VERSION ""

NS_ :

BS_:

BU_: AMB BMS ECU TEL OBC MEMORATOR MDI MC STR DRD MPPT DIST MST HVC

BO_ 808 HvcMcPrecharge: 4 HVC
 SG_ MotorPrechargeVoltage : 7|32@0- (1,0) [-2147483648|2147483647] "mV" Vector__XXX

BO_ 809 HvcMpptPrecharge: 4 HVC
 SG_ MpptPrechargeVoltage : 7|32@0- (1,0) [-2147483648|2147483647] "mV" Vector__XXX

BO_ 801 HVC_Fault: 3 HVC
 SG_ WatchdogFired : 0|1@1+ (1,0) [0|1] "" Vector__XXX
 SG_ DcdcFault : 1|1@1+ (1,0) [0|1] "" Vector__XXX
 SG_ DistFaultFlag : 2|1@1+ (1,0) [0|1] "" Vector__XXX
 SG_ UndercurrentFault : 3|1@1+ (1,0) [0|1] "" Vector__XXX
 SG_ OvercurrentFault : 4|1@1+ (1,0) [0|1] "" Vector__XXX
 SG_ MasterboardFault : 5|1@1+ (1,0) [0|1] "" Vector__XXX
 SG_ ImdFault : 6|1@1+ (1,0) [0|1] "" Vector__XXX
 SG_ EstopFault : 7|1@1+ (1,0) [0|1] "" Vector__XXX
 SG_ TelHeartbeatTimeout : 8|1@1+ (1,0) [0|1] "" Vector__XXX
 SG_ LvPowerupTimeout : 9|1@1+ (1,0) [0|1] "" Vector__XXX
 SG_ MpptPrechargeTimeout : 10|1@1+ (1,0) [0|1] "" Vector__XXX
 SG_ MotorPrechargeTimeout : 11|1@1+ (1,0) [0|1] "" Vector__XXX
 SG_ MotorDischargeTimeout : 12|1@1+ (1,0) [0|1] "" Vector__XXX
 SG_ MstCheckTimeout : 13|1@1+ (1,0) [0|1] "" Vector__XXX
 SG_ MstReadyTimeout : 14|1@1+ (1,0) [0|1] "" Vector__XXX
 SG_ MvpLvPowerupTimeout : 15|1@1+ (1,0) [0|1] "" Vector__XXX
 SG_ DcdcThermistorFault : 21|1@1+ (1,0) [0|1] "" Vector__XXX
 SG_ DistHeartbeatTimeout : 22|1@1+ (1,0) [0|1] "" Vector__XXX
 SG_ MstHeartbeatTimeout : 23|1@1+ (1,0) [0|1] "" Vector__XXX

BO_ 802 HVCHeartbeat: 4 HVC
 SG_ HVCTimeSinceBootUp : 23|16@0+ (1,0) [0|65535] "" Vector__XXX

BO_ 803 HVCLvPowerupSent: 1 HVC
 SG_ HVCLvPowerupSent : 0|8@1+ (1,0) [0|1] "" Vector__XXX

BO_ 804 HvcStatus: 1 HVC
 SG_ HVCState : 0|8@1+ (1,0) [0|14] "" Vector__XXX

BO_ 800 HVCShuntCurrent: 4 HVC
 SG_ PackCurrent : 7|32@0- (1,0) [-2147483648|2147483647] "mA" Vector__XXX

BO_ 807 HvcSuppVoltage: 4 HVC
 SG_ SuppVoltage : 7|32@0+ (1,0) [0|4294967295] "mV" Vector__XXX

BO_ 928 DISTHeartBeat: 3 DIST
 SG_ DISTHeartbeat : 0|8@1+ (1,0) [0|255] "" Vector__XXX
 SG_ DISTHeartbeatCounter : 15|16@0+ (1,0) [0|65535] "" Vector__XXX

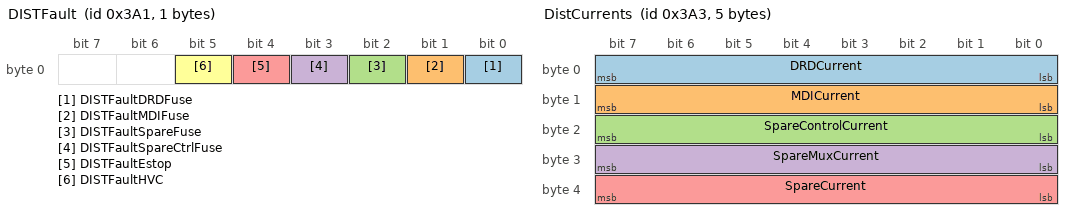
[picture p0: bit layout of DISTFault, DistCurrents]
BO_ 929 DISTFault: 1 DIST
 SG_ DISTFaultDRDFuse : 0|1@1+ (1,0) [0|1] "" Vector__XXX
 SG_ DISTFaultMDIFuse : 1|1@1+ (1,0) [0|1] "" Vector__XXX
 SG_ DISTFaultSpareFuse : 2|1@1+ (1,0) [0|1] "" Vector__XXX
 SG_ DISTFaultSpareCtrlFuse : 3|1@1+ (1,0) [0|1] "" Vector__XXX
 SG_ DISTFaultEstop : 4|1@1+ (1,0) [0|1] "" Vector__XXX
 SG_ DISTFaultHVC : 5|1@1+ (1,0) [0|1] "" Vector__XXX

BO_ 930 DISTLVOn: 1 DIST
 SG_ DISTLVOn : 0|8@1+ (1,0) [0|1] "" Vector__XXX

BO_ 931 DistCurrents: 5 DIST
 SG_ DRDCurrent : 0|8@1+ (5,0) [0|1275] "mA" Vector__XXX
 SG_ MDICurrent : 8|8@1+ (5,0) [0|1275] "mA" Vector__XXX
 SG_ SpareControlCurrent : 16|8@1+ (5,0) [0|1275] "mA" Vector__XXX
 SG_ SpareMuxCurrent : 24|8@1+ (5,0) [0|1275] "mA" Vector__XXX
 SG_ SpareCurrent : 32|8@1+ (5,0) [0|1275] "mA" Vector__XXX

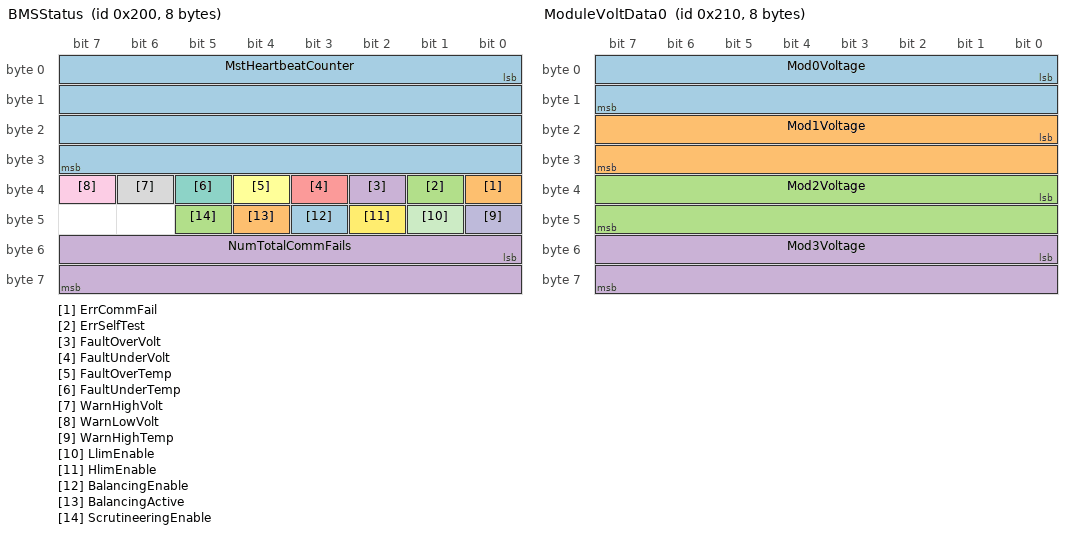
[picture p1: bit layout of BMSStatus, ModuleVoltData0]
BO_ 512 BMSStatus: 8 MST
 SG_ MstHeartbeatCounter : 0|32@1+ (1,0) [0|4294967295] "" Vector__XXX
 SG_ ErrCommFail : 32|1@1+ (1,0) [0|1] "" Vector__XXX
 SG_ ErrSelfTest : 33|1@1+ (1,0) [0|1] "" Vector__XXX
 SG_ FaultOverVolt : 34|1@1+ (1,0) [0|1] "" Vector__XXX
 SG_ FaultUnderVolt : 35|1@1+ (1,0) [0|1] "" Vector__XXX
 SG_ FaultOverTemp : 36|1@1+ (1,0) [0|1] "" Vector__XXX
 SG_ FaultUnderTemp : 37|1@1+ (1,0) [0|1] "" Vector__XXX
 SG_ WarnHighVolt : 38|1@1+ (1,0) [0|1] "" Vector__XXX
 SG_ WarnLowVolt : 39|1@1+ (1,0) [0|1] "" Vector__XXX
 SG_ WarnHighTemp : 40|1@1+ (1,0) [0|1] "" Vector__XXX
 SG_ LlimEnable : 41|1@1+ (1,0) [0|1] "" Vector__XXX
 SG_ HlimEnable : 42|1@1+ (1,0) [0|1] "" Vector__XXX
 SG_ BalancingEnable : 43|1@1+ (1,0) [0|1] "" Vector__XXX
 SG_ BalancingActive : 44|1@1+ (1,0) [0|1] "" Vector__XXX
 SG_ ScrutineeringEnable : 45|1@1+ (1,0) [0|1] "" Vector__XXX
 SG_ NumTotalCommFails : 48|16@1+ (1,0) [0|65535] "" Vector__XXX

BO_ 513 VoltSummary: 6 MST
 SG_ TotalVoltage : 0|32@1+ (1,0) [0|4294967295] "mV" Vector__XXX
 SG_ MinVoltModuleIdx : 32|8@1+ (1,0) [0|255] "" Vector__XXX
 SG_ MaxVoltModuleIdx : 40|8@1+ (1,0) [0|255] "" Vector__XXX

BO_ 514 TempSummary: 4 MST
 SG_ AvgTemp : 0|16@1- (1,0) [-32768|32767] "degC" Vector__XXX
 SG_ MinTempModuleIdx : 16|8@1+ (1,0) [0|255] "" Vector__XXX
 SG_ MaxTempModuleIdx : 24|8@1+ (1,0) [0|255] "" Vector__XXX

BO_ 528 ModuleVoltData0: 8 MST
 SG_ Mod0Voltage : 0|16@1+ (1,0) [0|65535] "mV" Vector__XXX
 SG_ Mod1Voltage : 16|16@1+ (1,0) [0|65535] "mV" Vector__XXX
 SG_ Mod2Voltage : 32|16@1+ (1,0) [0|65535] "mV" Vector__XXX
 SG_ Mod3Voltage : 48|16@1+ (1,0) [0|65535] "mV" Vector__XXX

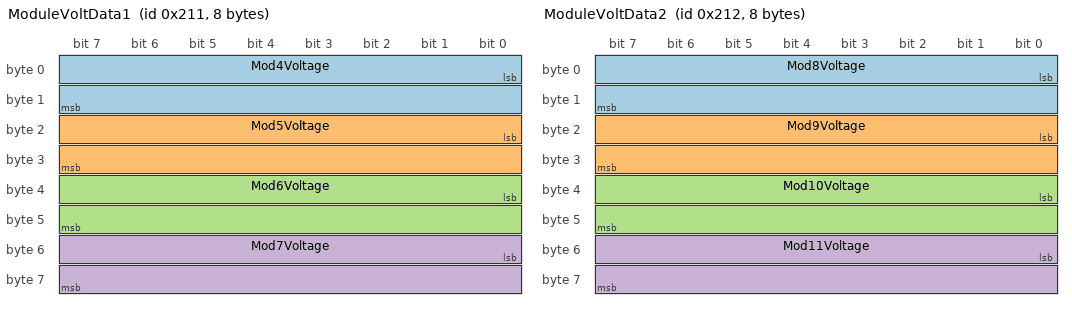
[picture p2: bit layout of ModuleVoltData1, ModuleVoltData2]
BO_ 529 ModuleVoltData1: 8 MST
 SG_ Mod4Voltage : 0|16@1+ (1,0) [0|65535] "mV" Vector__XXX
 SG_ Mod5Voltage : 16|16@1+ (1,0) [0|65535] "mV" Vector__XXX
 SG_ Mod6Voltage : 32|16@1+ (1,0) [0|65535] "mV" Vector__XXX
 SG_ Mod7Voltage : 48|16@1+ (1,0) [0|65535] "mV" Vector__XXX

BO_ 530 ModuleVoltData2: 8 MST
 SG_ Mod8Voltage : 0|16@1+ (1,0) [0|65535] "mV" Vector__XXX
 SG_ Mod9Voltage : 16|16@1+ (1,0) [0|65535] "mV" Vector__XXX
 SG_ Mod10Voltage : 32|16@1+ (1,0) [0|65535] "mV" Vector__XXX
 SG_ Mod11Voltage : 48|16@1+ (1,0) [0|65535] "mV" Vector__XXX

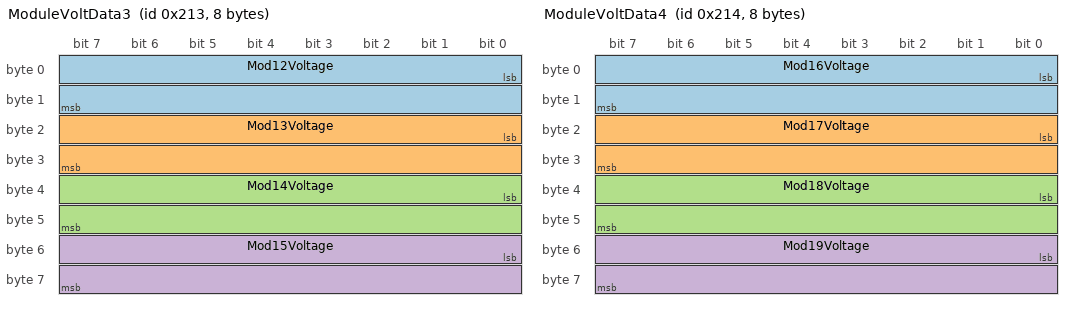
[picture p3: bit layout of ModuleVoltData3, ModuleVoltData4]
BO_ 531 ModuleVoltData3: 8 MST
 SG_ Mod12Voltage : 0|16@1+ (1,0) [0|65535] "mV" Vector__XXX
 SG_ Mod13Voltage : 16|16@1+ (1,0) [0|65535] "mV" Vector__XXX
 SG_ Mod14Voltage : 32|16@1+ (1,0) [0|65535] "mV" Vector__XXX
 SG_ Mod15Voltage : 48|16@1+ (1,0) [0|65535] "mV" Vector__XXX

BO_ 532 ModuleVoltData4: 8 MST
 SG_ Mod16Voltage : 0|16@1+ (1,0) [0|65535] "mV" Vector__XXX
 SG_ Mod17Voltage : 16|16@1+ (1,0) [0|65535] "mV" Vector__XXX
 SG_ Mod18Voltage : 32|16@1+ (1,0) [0|65535] "mV" Vector__XXX
 SG_ Mod19Voltage : 48|16@1+ (1,0) [0|65535] "mV" Vector__XXX

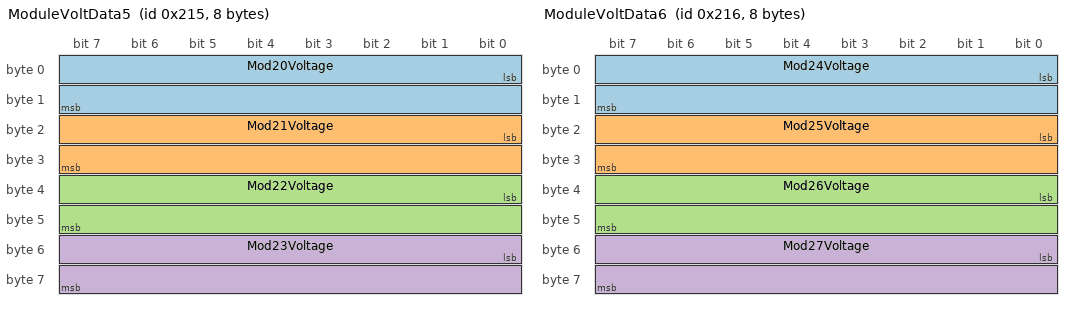
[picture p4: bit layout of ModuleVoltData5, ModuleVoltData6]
BO_ 533 ModuleVoltData5: 8 MST
 SG_ Mod20Voltage : 0|16@1+ (1,0) [0|65535] "mV" Vector__XXX
 SG_ Mod21Voltage : 16|16@1+ (1,0) [0|65535] "mV" Vector__XXX
 SG_ Mod22Voltage : 32|16@1+ (1,0) [0|65535] "mV" Vector__XXX
 SG_ Mod23Voltage : 48|16@1+ (1,0) [0|65535] "mV" Vector__XXX

BO_ 534 ModuleVoltData6: 8 MST
 SG_ Mod24Voltage : 0|16@1+ (1,0) [0|65535] "mV" Vector__XXX
 SG_ Mod25Voltage : 16|16@1+ (1,0) [0|65535] "mV" Vector__XXX
 SG_ Mod26Voltage : 32|16@1+ (1,0) [0|65535] "mV" Vector__XXX
 SG_ Mod27Voltage : 48|16@1+ (1,0) [0|65535] "mV" Vector__XXX

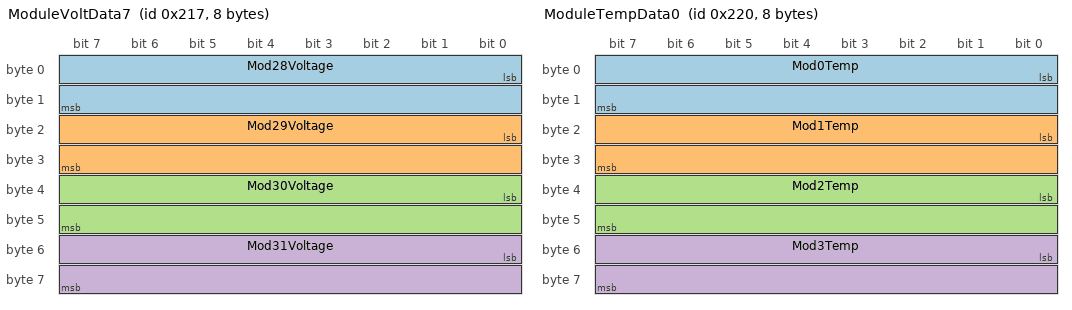
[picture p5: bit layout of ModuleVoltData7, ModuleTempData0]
BO_ 535 ModuleVoltData7: 8 MST
 SG_ Mod28Voltage : 0|16@1+ (1,0) [0|65535] "mV" Vector__XXX
 SG_ Mod29Voltage : 16|16@1+ (1,0) [0|65535] "mV" Vector__XXX
 SG_ Mod30Voltage : 32|16@1+ (1,0) [0|65535] "mV" Vector__XXX
 SG_ Mod31Voltage : 48|16@1+ (1,0) [0|65535] "mV" Vector__XXX

BO_ 544 ModuleTempData0: 8 MST
 SG_ Mod0Temp : 0|16@1- (1,0) [-32768|32767] "degC" Vector__XXX
 SG_ Mod1Temp : 16|16@1- (1,0) [-32768|32767] "degC" Vector__XXX
 SG_ Mod2Temp : 32|16@1- (1,0) [-32768|32767] "degC" Vector__XXX
 SG_ Mod3Temp : 48|16@1- (1,0) [-32768|32767] "degC" Vector__XXX

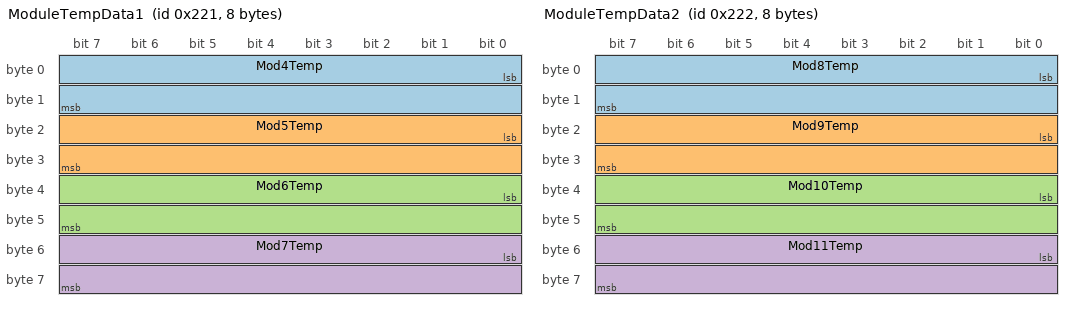
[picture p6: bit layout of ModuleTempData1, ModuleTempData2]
BO_ 545 ModuleTempData1: 8 MST
 SG_ Mod4Temp : 0|16@1- (1,0) [-32768|32767] "degC" Vector__XXX
 SG_ Mod5Temp : 16|16@1- (1,0) [-32768|32767] "degC" Vector__XXX
 SG_ Mod6Temp : 32|16@1- (1,0) [-32768|32767] "degC" Vector__XXX
 SG_ Mod7Temp : 48|16@1- (1,0) [-32768|32767] "degC" Vector__XXX

BO_ 546 ModuleTempData2: 8 MST
 SG_ Mod8Temp : 0|16@1- (1,0) [-32768|32767] "degC" Vector__XXX
 SG_ Mod9Temp : 16|16@1- (1,0) [-32768|32767] "degC" Vector__XXX
 SG_ Mod10Temp : 32|16@1- (1,0) [-32768|32767] "degC" Vector__XXX
 SG_ Mod11Temp : 48|16@1- (1,0) [-32768|32767] "degC" Vector__XXX

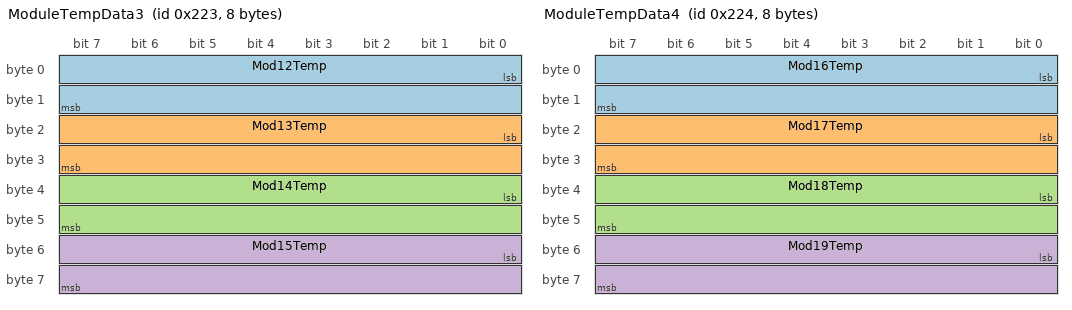
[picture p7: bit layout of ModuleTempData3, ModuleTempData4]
BO_ 547 ModuleTempData3: 8 MST
 SG_ Mod12Temp : 0|16@1- (1,0) [-32768|32767] "degC" Vector__XXX
 SG_ Mod13Temp : 16|16@1- (1,0) [-32768|32767] "degC" Vector__XXX
 SG_ Mod14Temp : 32|16@1- (1,0) [-32768|32767] "degC" Vector__XXX
 SG_ Mod15Temp : 48|16@1- (1,0) [-32768|32767] "degC" Vector__XXX

BO_ 548 ModuleTempData4: 8 MST
 SG_ Mod16Temp : 0|16@1- (1,0) [-32768|32767] "degC" Vector__XXX
 SG_ Mod17Temp : 16|16@1- (1,0) [-32768|32767] "degC" Vector__XXX
 SG_ Mod18Temp : 32|16@1- (1,0) [-32768|32767] "degC" Vector__XXX
 SG_ Mod19Temp : 48|16@1- (1,0) [-32768|32767] "degC" Vector__XXX

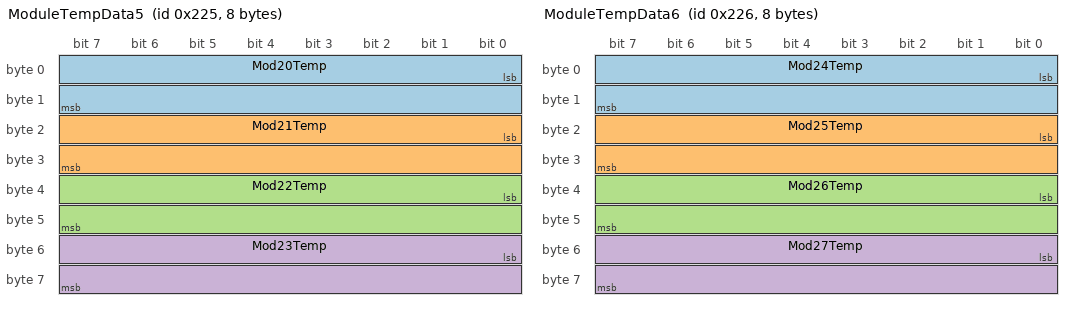
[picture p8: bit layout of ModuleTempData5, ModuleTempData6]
BO_ 549 ModuleTempData5: 8 MST
 SG_ Mod20Temp : 0|16@1- (1,0) [-32768|32767] "degC" Vector__XXX
 SG_ Mod21Temp : 16|16@1- (1,0) [-32768|32767] "degC" Vector__XXX
 SG_ Mod22Temp : 32|16@1- (1,0) [-32768|32767] "degC" Vector__XXX
 SG_ Mod23Temp : 48|16@1- (1,0) [-32768|32767] "degC" Vector__XXX

BO_ 550 ModuleTempData6: 8 MST
 SG_ Mod24Temp : 0|16@1- (1,0) [-32768|32767] "degC" Vector__XXX
 SG_ Mod25Temp : 16|16@1- (1,0) [-32768|32767] "degC" Vector__XXX
 SG_ Mod26Temp : 32|16@1- (1,0) [-32768|32767] "degC" Vector__XXX
 SG_ Mod27Temp : 48|16@1- (1,0) [-32768|32767] "degC" Vector__XXX

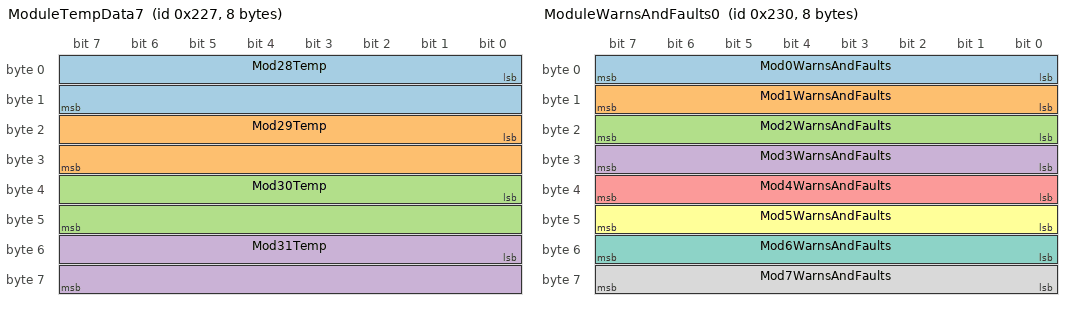
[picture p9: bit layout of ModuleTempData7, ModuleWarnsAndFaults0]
BO_ 551 ModuleTempData7: 8 MST
 SG_ Mod28Temp : 0|16@1- (1,0) [-32768|32767] "degC" Vector__XXX
 SG_ Mod29Temp : 16|16@1- (1,0) [-32768|32767] "degC" Vector__XXX
 SG_ Mod30Temp : 32|16@1- (1,0) [-32768|32767] "degC" Vector__XXX
 SG_ Mod31Temp : 48|16@1- (1,0) [-32768|32767] "degC" Vector__XXX

BO_ 560 ModuleWarnsAndFaults0: 8 MST
 SG_ Mod0WarnsAndFaults : 0|8@1+ (1,0) [0|255] "" Vector__XXX
 SG_ Mod1WarnsAndFaults : 8|8@1+ (1,0) [0|255] "" Vector__XXX
 SG_ Mod2WarnsAndFaults : 16|8@1+ (1,0) [0|255] "" Vector__XXX
 SG_ Mod3WarnsAndFaults : 24|8@1+ (1,0) [0|255] "" Vector__XXX
 SG_ Mod4WarnsAndFaults : 32|8@1+ (1,0) [0|255] "" Vector__XXX
 SG_ Mod5WarnsAndFaults : 40|8@1+ (1,0) [0|255] "" Vector__XXX
 SG_ Mod6WarnsAndFaults : 48|8@1+ (1,0) [0|255] "" Vector__XXX
 SG_ Mod7WarnsAndFaults : 56|8@1+ (1,0) [0|255] "" Vector__XXX

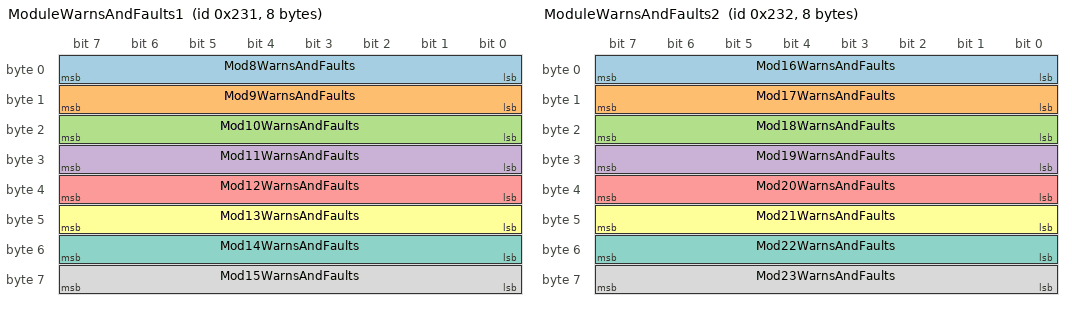
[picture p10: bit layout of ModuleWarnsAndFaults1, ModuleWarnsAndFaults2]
BO_ 561 ModuleWarnsAndFaults1: 8 MST
 SG_ Mod8WarnsAndFaults : 0|8@1+ (1,0) [0|255] "" Vector__XXX
 SG_ Mod9WarnsAndFaults : 8|8@1+ (1,0) [0|255] "" Vector__XXX
 SG_ Mod10WarnsAndFaults : 16|8@1+ (1,0) [0|255] "" Vector__XXX
 SG_ Mod11WarnsAndFaults : 24|8@1+ (1,0) [0|255] "" Vector__XXX
 SG_ Mod12WarnsAndFaults : 32|8@1+ (1,0) [0|255] "" Vector__XXX
 SG_ Mod13WarnsAndFaults : 40|8@1+ (1,0) [0|255] "" Vector__XXX
 SG_ Mod14WarnsAndFaults : 48|8@1+ (1,0) [0|255] "" Vector__XXX
 SG_ Mod15WarnsAndFaults : 56|8@1+ (1,0) [0|255] "" Vector__XXX

BO_ 562 ModuleWarnsAndFaults2: 8 MST
 SG_ Mod16WarnsAndFaults : 0|8@1+ (1,0) [0|255] "" Vector__XXX
 SG_ Mod17WarnsAndFaults : 8|8@1+ (1,0) [0|255] "" Vector__XXX
 SG_ Mod18WarnsAndFaults : 16|8@1+ (1,0) [0|255] "" Vector__XXX
 SG_ Mod19WarnsAndFaults : 24|8@1+ (1,0) [0|255] "" Vector__XXX
 SG_ Mod20WarnsAndFaults : 32|8@1+ (1,0) [0|255] "" Vector__XXX
 SG_ Mod21WarnsAndFaults : 40|8@1+ (1,0) [0|255] "" Vector__XXX
 SG_ Mod22WarnsAndFaults : 48|8@1+ (1,0) [0|255] "" Vector__XXX
 SG_ Mod23WarnsAndFaults : 56|8@1+ (1,0) [0|255] "" Vector__XXX

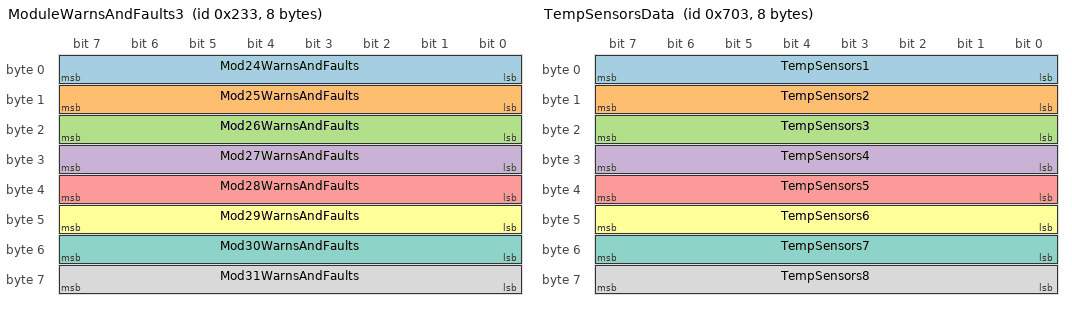
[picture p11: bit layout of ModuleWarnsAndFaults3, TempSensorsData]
BO_ 563 ModuleWarnsAndFaults3: 8 MST
 SG_ Mod24WarnsAndFaults : 0|8@1+ (1,0) [0|255] "" Vector__XXX
 SG_ Mod25WarnsAndFaults : 8|8@1+ (1,0) [0|255] "" Vector__XXX
 SG_ Mod26WarnsAndFaults : 16|8@1+ (1,0) [0|255] "" Vector__XXX
 SG_ Mod27WarnsAndFaults : 24|8@1+ (1,0) [0|255] "" Vector__XXX
 SG_ Mod28WarnsAndFaults : 32|8@1+ (1,0) [0|255] "" Vector__XXX
 SG_ Mod29WarnsAndFaults : 40|8@1+ (1,0) [0|255] "" Vector__XXX
 SG_ Mod30WarnsAndFaults : 48|8@1+ (1,0) [0|255] "" Vector__XXX
 SG_ Mod31WarnsAndFaults : 56|8@1+ (1,0) [0|255] "" Vector__XXX

BO_ 515 BalanceData: 4 MST
 SG_ BalanceBitmap : 0|32@1+ (1,0) [0|4294967295] "" Vector__XXX

BO_ 1793 VoltageSensorsData: 8 AMB
 SG_ VoltSensor1 : 0|32@1- (1,0) [0|0] "V" Vector__XXX
 SG_ VoltSensor2 : 32|32@1- (1,0) [0|0] "V" Vector__XXX

BO_ 1794 CurrentSensorsData: 8 AMB
 SG_ CurrentSensor1 : 0|32@1- (1,0) [0|0] "A" Vector__XXX
 SG_ CurrentSensor2 : 32|32@1- (1,0) [0|0] "A" Vector__XXX

BO_ 1795 TempSensorsData: 8 AMB
 SG_ TempSensors1 : 0|8@1+ (1,0) [0|0] "C" Vector__XXX
 SG_ TempSensors2 : 8|8@1+ (1,0) [0|0] "C" Vector__XXX
 SG_ TempSensors3 : 16|8@1+ (1,0) [0|0] "C" Vector__XXX
 SG_ TempSensors4 : 24|8@1+ (1,0) [0|0] "C" Vector__XXX
 SG_ TempSensors5 : 32|8@1+ (1,0) [0|0] "C" Vector__XXX
 SG_ TempSensors6 : 40|8@1+ (1,0) [0|0] "C" Vector__XXX
 SG_ TempSensors7 : 48|8@1+ (1,0) [0|0] "C" Vector__XXX
 SG_ TempSensors8 : 56|8@1+ (1,0) [0|0] "C" Vector__XXX

BO_ 1570 Faults: 7 BMS
 SG_ SlaveBoardComm : 0|1@1+ (1,0) [0|0] "" Vector__XXX
 SG_ BMSSelfTest : 1|1@1+ (1,0) [0|0] "" Vector__XXX
 SG_ OverTemp : 2|1@1+ (1,0) [0|0] "" Vector__XXX
 SG_ UnderVoltage : 3|1@1+ (1,0) [0|0] "" Vector__XXX
 SG_ OverVoltage : 4|1@1+ (1,0) [0|0] "" Vector__XXX
 SG_ IsoLost : 5|1@1+ (1,0) [0|0] "" Vector__XXX
 SG_ ChargeOvercurrent : 6|1@1+ (1,0) [0|0] "" Vector__XXX
 SG_ VoltOutofRange : 7|1@1+ (1,0) [0|0] "" Vector__XXX
 SG_ TempOutofRange : 8|1@1+ (1,0) [0|0] "" Vector__XXX
 SG_ PackBalancingActive : 9|1@1+ (1,0) [0|0] "" Vector__XXX
 SG_ LLIMActive : 10|1@1+ (1,0) [0|0] "" Vector__XXX
 SG_ HLIMActive : 11|1@1+ (1,0) [0|0] "" Vector__XXX
 SG_ ChargeOverTemp : 12|1@1+ (1,0) [0|0] "" Vector__XXX
 SG_ LowVoltage : 13|1@1+ (1,0) [0|0] "" Vector__XXX
 SG_ HighVoltage : 14|1@1+ (1,0) [0|0] "" Vector__XXX
 SG_ LowTemp : 15|1@1+ (1,0) [0|0] "" Vector__XXX
 SG_ HighTemp : 16|1@1+ (1,0) [0|0] "" Vector__XXX
 SG_ RequestRegenOff : 17|1@1+ (1,0) [0|0] "" Vector__XXX
 SG_ NoECUCurrentMessage : 18|1@1+ (1,0) [0|0] "" Vector__XXX

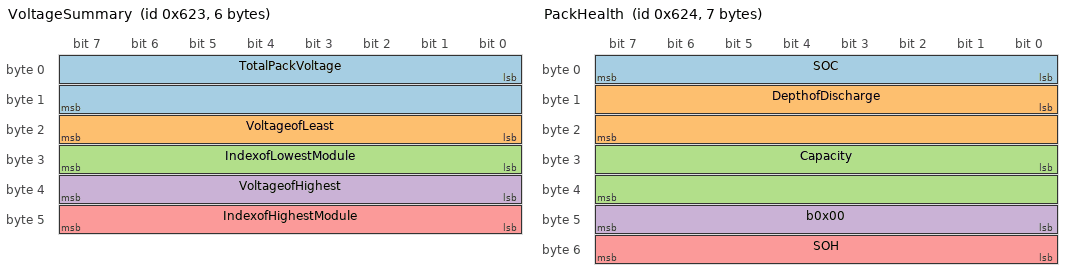
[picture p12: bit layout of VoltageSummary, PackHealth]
BO_ 1571 VoltageSummary: 6 BMS
 SG_ TotalPackVoltage : 0|16@1+ (0.0021367521368,0) [0|140] "V" Vector__XXX
 SG_ VoltageofLeast : 16|8@1+ (0.019607843137,0) [0|5] "V" Vector__XXX
 SG_ IndexofLowestModule : 24|8@1+ (1,0) [0|31] "" Vector__XXX
 SG_ VoltageofHighest : 32|8@1+ (0.019607843137,0) [0|5] "V" Vector__XXX
 SG_ IndexofHighestModule : 40|8@1+ (1,0) [0|31] "" Vector__XXX

BO_ 1572 PackHealth: 7 BMS
 SG_ SOC : 0|8@1+ (1,0) [0|100] "%" Vector__XXX
 SG_ DepthofDischarge : 8|16@1+ (1,0) [0|65] "kAH" Vector__XXX
 SG_ Capacity : 24|16@1+ (1,0) [0|65] "kAH" Vector__XXX
 SG_ b0x00 : 40|8@1+ (1,0) [0|0] "" Vector__XXX
 SG_ SOH : 48|8@1+ (1,0) [0|0] "" Vector__XXX

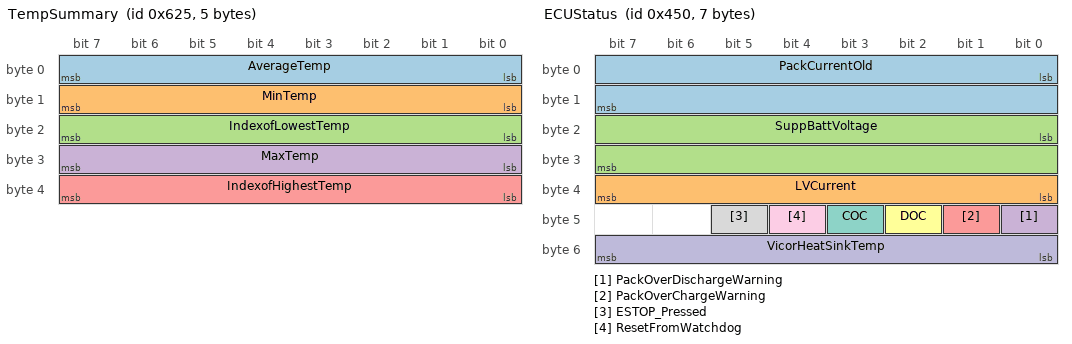
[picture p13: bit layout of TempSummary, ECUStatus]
BO_ 1573 TempSummary: 5 BMS
 SG_ AverageTemp : 0|8@1- (1,0) [-127|127] "C" Vector__XXX
 SG_ MinTemp : 8|8@1- (1,0) [-127|127] "C" Vector__XXX
 SG_ IndexofLowestTemp : 16|8@1+ (1,0) [0|31] "" Vector__XXX
 SG_ MaxTemp : 24|8@1- (1,0) [-127|127] "C" Vector__XXX
 SG_ IndexofHighestTemp : 32|8@1+ (1,0) [0|31] "" Vector__XXX

BO_ 1574 ModuleVoltages: 5 BMS
 SG_ MultiplexingBits M : 0|3@1+ (1,0) [0|0] "" Vector__XXX
 SG_ Voltage1 m0 : 8|8@1+ (0.019607843137,0) [0|5] "V" Vector__XXX
 SG_ Voltage2 m0 : 16|8@1+ (0.019607843137,0) [0|5] "V" Vector__XXX
 SG_ Voltage3 m0 : 24|8@1+ (0.019607843137,0) [0|5] "V" Vector__XXX
 SG_ Voltage4 m0 : 32|8@1+ (0.019607843137,0) [0|5] "V" Vector__XXX
 SG_ Voltage5 m1 : 8|8@1+ (0.019607843137,0) [0|5] "V" Vector__XXX
 SG_ Voltage6 m1 : 16|8@1+ (0.019607843137,0) [0|5] "V" Vector__XXX
 SG_ Voltage7 m1 : 24|8@1+ (0.019607843137,0) [0|5] "V" Vector__XXX
 SG_ Voltage8 m1 : 32|8@1+ (0.019607843137,0) [0|5] "V" Vector__XXX
 SG_ Voltage9 m2 : 8|8@1+ (0.019607843137,0) [0|5] "V" Vector__XXX
 SG_ Voltage10 m2 : 16|8@1+ (0.019607843137,0) [0|5] "V" Vector__XXX
 SG_ Voltage11 m2 : 24|8@1+ (0.019607843137,0) [0|5] "V" Vector__XXX
 SG_ Voltage12 m2 : 32|8@1+ (0.019607843137,0) [0|5] "V" Vector__XXX
 SG_ Voltage13 m3 : 8|8@1+ (0.019607843137,0) [0|5] "V" Vector__XXX
 SG_ Voltage14 m3 : 16|8@1+ (0.019607843137,0) [0|5] "V" Vector__XXX
 SG_ Voltage15 m3 : 24|8@1+ (0.019607843137,0) [0|5] "V" Vector__XXX
 SG_ Voltage16 m3 : 32|8@1+ (0.019607843137,0) [0|5] "V" Vector__XXX
 SG_ Voltage17 m4 : 8|8@1+ (0.019607843137,0) [0|5] "V" Vector__XXX
 SG_ Voltage18 m4 : 16|8@1+ (0.019607843137,0) [0|5] "V" Vector__XXX
 SG_ Voltage19 m4 : 24|8@1+ (0.019607843137,0) [0|5] "V" Vector__XXX
 SG_ Voltage20 m4 : 32|8@1+ (0.019607843137,0) [0|5] "V" Vector__XXX
 SG_ Voltage21 m5 : 8|8@1+ (0.019607843137,0) [0|5] "V" Vector__XXX
 SG_ Voltage22 m5 : 16|8@1+ (0.019607843137,0) [0|5] "V" Vector__XXX
 SG_ Voltage23 m5 : 24|8@1+ (0.019607843137,0) [0|5] "V" Vector__XXX
 SG_ Voltage24 m5 : 32|8@1+ (0.019607843137,0) [0|5] "V" Vector__XXX
 SG_ Voltage25 m6 : 8|8@1+ (0.019607843137,0) [0|5] "V" Vector__XXX
 SG_ Voltage26 m6 : 16|8@1+ (0.019607843137,0) [0|5] "V" Vector__XXX
 SG_ Voltage27 m6 : 24|8@1+ (0.019607843137,0) [0|5] "V" Vector__XXX
 SG_ Voltage28 m6 : 32|8@1+ (0.019607843137,0) [0|5] "V" Vector__XXX
 SG_ Voltage29 m7 : 8|8@1+ (0.019607843137,0) [0|5] "V" Vector__XXX
 SG_ Voltage30 m7 : 16|8@1+ (0.019607843137,0) [0|5] "V" Vector__XXX
 SG_ Voltage31 m7 : 24|8@1+ (0.019607843137,0) [0|5] "V" Vector__XXX
 SG_ Voltage32 m7 : 32|8@1+ (0.019607843137,0) [0|5] "V" Vector__XXX

BO_ 1575 ModuleTemps: 5 BMS
 SG_ MultiplexingBits M : 0|3@1+ (1,0) [0|0] "" Vector__XXX
 SG_ Temp1 m0 : 8|8@1- (1,0) [-127|127] "C" Vector__XXX
 SG_ Temp2 m0 : 16|8@1- (1,0) [-127|127] "C" Vector__XXX
 SG_ Temp3 m0 : 24|8@1- (1,0) [-127|127] "C" Vector__XXX
 SG_ Temp4 m0 : 32|8@1- (1,0) [-127|127] "C" Vector__XXX
 SG_ Temp5 m1 : 8|8@1+ (1,0) [4294967169|127] "C" Vector__XXX
 SG_ Temp6 m1 : 16|8@1+ (1,0) [4294967169|127] "C" Vector__XXX
 SG_ Temp7 m1 : 24|8@1+ (1,0) [4294967169|127] "C" Vector__XXX
 SG_ Temp8 m1 : 32|8@1+ (1,0) [4294967169|127] "C" Vector__XXX
 SG_ Temp9 m2 : 8|8@1+ (1,0) [4294967169|127] "C" Vector__XXX
 SG_ Temp10 m2 : 16|8@1+ (1,0) [4294967169|127] "C" Vector__XXX
 SG_ Temp11 m2 : 24|8@1+ (1,0) [4294967169|127] "C" Vector__XXX
 SG_ Temp12 m2 : 32|8@1+ (1,0) [4294967169|127] "C" Vector__XXX
 SG_ Temp13 m3 : 8|8@1+ (1,0) [4294967169|127] "C" Vector__XXX
 SG_ Temp14 m3 : 16|8@1+ (1,0) [4294967169|127] "C" Vector__XXX
 SG_ Temp15 m3 : 24|8@1+ (1,0) [4294967169|127] "C" Vector__XXX
 SG_ Temp16 m3 : 32|8@1+ (1,0) [4294967169|127] "C" Vector__XXX
 SG_ Temp17 m4 : 8|8@1+ (1,0) [4294967169|127] "C" Vector__XXX
 SG_ Temp18 m4 : 16|8@1+ (1,0) [4294967169|127] "C" Vector__XXX
 SG_ Temp19 m4 : 24|8@1+ (1,0) [4294967169|127] "C" Vector__XXX
 SG_ Temp20 m4 : 32|8@1+ (1,0) [4294967169|127] "C" Vector__XXX
 SG_ Temp21 m5 : 8|8@1+ (1,0) [4294967169|127] "C" Vector__XXX
 SG_ Temp22 m5 : 16|8@1+ (1,0) [4294967169|127] "C" Vector__XXX
 SG_ Temp23 m5 : 24|8@1+ (1,0) [4294967169|127] "C" Vector__XXX
 SG_ Temp24 m5 : 32|8@1+ (1,0) [4294967169|127] "C" Vector__XXX
 SG_ Temp25 m6 : 8|8@1+ (1,0) [4294967169|127] "C" Vector__XXX
 SG_ Temp26 m6 : 16|8@1+ (1,0) [4294967169|127] "C" Vector__XXX
 SG_ Temp27 m6 : 24|8@1+ (1,0) [4294967169|127] "C" Vector__XXX
 SG_ Temp28 m6 : 32|8@1+ (1,0) [4294967169|127] "C" Vector__XXX
 SG_ Temp29 m7 : 8|8@1+ (1,0) [4294967169|127] "C" Vector__XXX
 SG_ Temp30 m7 : 16|8@1+ (1,0) [4294967169|127] "C" Vector__XXX
 SG_ Temp31 m7 : 24|8@1+ (1,0) [4294967169|127] "C" Vector__XXX
 SG_ Temp32 m7 : 32|8@1+ (1,0) [4294967169|127] "C" Vector__XXX

BO_ 1104 ECUStatus: 7 ECU
 SG_ PackCurrentOld : 0|16@1- (0.015259021897,0) [-127|127] "A" Vector__XXX
 SG_ LVCurrent : 32|8@1+ (0.11764705882,0) [0|30] "A" Vector__XXX
 SG_ SuppBattVoltage : 16|16@1+ (0.001,0) [0|16] "V" Vector__XXX
 SG_ PackOverDischargeWarning : 40|1@1+ (1,0) [0|0] "" Vector__XXX
 SG_ PackOverChargeWarning : 41|1@1+ (1,0) [0|0] "" Vector__XXX
 SG_ DOC : 42|1@1+ (1,0) [0|0] "" Vector__XXX
 SG_ COC : 43|1@1+ (1,0) [0|0] "" Vector__XXX
 SG_ ESTOP_Pressed : 45|1@1+ (1,0) [0|0] "" Vector__XXX
 SG_ ResetFromWatchdog : 44|1@1+ (1,0) [0|0] "" Vector__XXX
 SG_ VicorHeatSinkTemp : 48|8@1+ (1,0) [-127|127] "" Vector__XXX

BO_ 1280 MDITimeSinceBootup: 4 MDI
 SG_ MDITimeSinceBootUp : 0|32@1+ (1,0) [0|0] "s" Vector__XXX

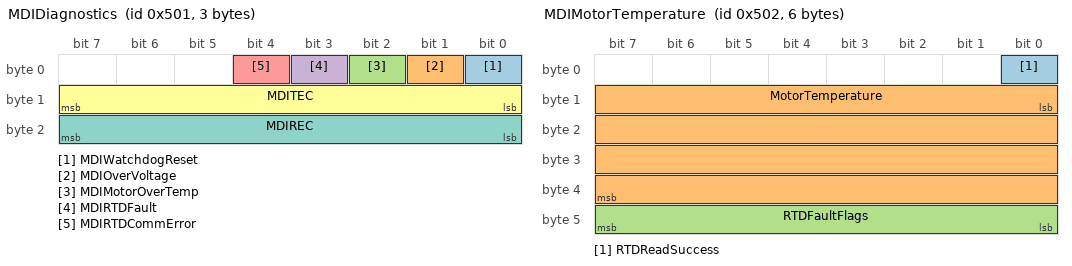
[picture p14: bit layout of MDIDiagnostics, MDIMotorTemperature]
BO_ 1281 MDIDiagnostics: 3 MDI
 SG_ MDIWatchdogReset : 0|1@1+ (1,0) [0|1] "" Vector__XXX
 SG_ MDIOverVoltage : 1|1@1+ (1,0) [0|1] "" Vector__XXX
 SG_ MDIMotorOverTemp : 2|1@1+ (1,0) [0|1] "" Vector__XXX
 SG_ MDIRTDFault : 3|1@1+ (1,0) [0|1] "" Vector__XXX
 SG_ MDIRTDCommError : 4|1@1+ (1,0) [0|1] "" Vector__XXX
 SG_ MDITEC : 8|8@1+ (1,0) [0|255] "" Vector__XXX
 SG_ MDIREC : 16|8@1+ (1,0) [0|255] "" Vector__XXX

BO_ 1282 MDIMotorTemperature: 6 MDI
 SG_ RTDReadSuccess : 0|1@1+ (1,0) [0|1] "" Vector__XXX
 SG_ MotorTemperature : 8|32@1- (1,0) [-100|300] "degC" Vector__XXX
 SG_ RTDFaultFlags : 40|8@1+ (1,0) [0|255] "" Vector__XXX

BO_ 1283 MDIMCUHealth: 4 MDI
 SG_ MCUVoltage : 0|16@1+ (1,0) [0|65535] "mV" Vector__XXX
 SG_ MCUTemperature : 16|16@1- (1,0) [-40|125] "degC" Vector__XXX

BO_ 1409 STRTimeSinceBootup: 4 STR
 SG_ STRTimeSinceBootUp : 0|32@1+ (1,0) [0|0] "s" Vector__XXX

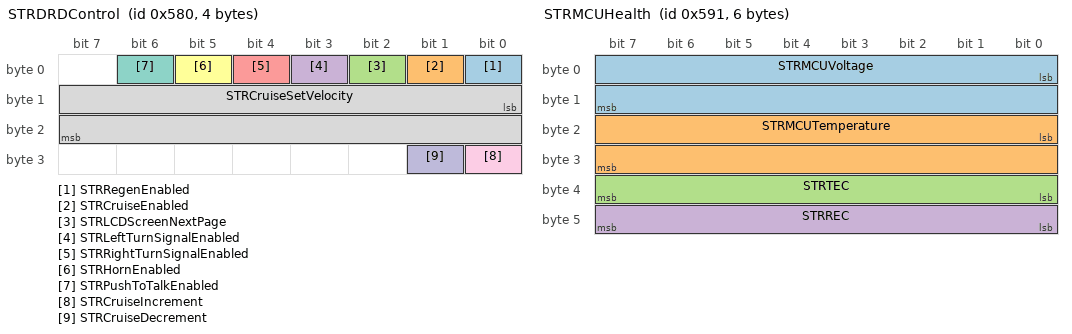
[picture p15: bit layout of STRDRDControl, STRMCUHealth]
BO_ 1408 STRDRDControl: 4 STR
 SG_ STRRegenEnabled : 0|1@1+ (1,0) [0|1] "" Vector__XXX
 SG_ STRCruiseEnabled : 1|1@1+ (1,0) [0|1] "" Vector__XXX
 SG_ STRLCDScreenNextPage : 2|1@1+ (1,0) [0|1] "" Vector__XXX
 SG_ STRLeftTurnSignalEnabled : 3|1@1+ (1,0) [0|1] "" Vector__XXX
 SG_ STRRightTurnSignalEnabled : 4|1@1+ (1,0) [0|1] "" Vector__XXX
 SG_ STRHornEnabled : 5|1@1+ (1,0) [0|1] "" Vector__XXX
 SG_ STRPushToTalkEnabled : 6|1@1+ (1,0) [0|1] "" Vector__XXX
 SG_ STRCruiseSetVelocity : 8|16@1+ (1,0) [0|0] "km/hr" Vector__XXX
 SG_ STRCruiseIncrement : 24|1@1+ (1,0) [0|1] "" Vector__XXX
 SG_ STRCruiseDecrement : 25|1@1+ (1,0) [0|1] "" Vector__XXX

BO_ 1410 STRDiagnostics : 1 STR
 SG_ STRWatchdogReset : 0|1@1+ (1,0) [0|0] "" Vector__XXX

BO_ 1425 STRMCUHealth: 6 STR
 SG_ STRMCUVoltage : 0|16@1+ (1,0) [0|65535] "mV" Vector__XXX
 SG_ STRMCUTemperature : 16|16@1- (1,0) [-40|125] "degC" Vector__XXX
 SG_ STRTEC : 32|8@1+ (1,0) [0|255] "" Vector__XXX
 SG_ STRREC : 40|8@1+ (1,0) [0|255] "" Vector__XXX

BO_ 1426 STRFlags: 1 STR
 SG_ STRMCUOverTemp : 0|1@1+ (1,0) [0|1] "" Vector__XXX
 SG_ STRMCUUnderVoltage : 1|1@1+ (1,0) [0|1] "" Vector__XXX

BO_ 1576 ModuleStatuses: 5 BMS
 SG_ MultiplexingBits M : 0|3@1+ (1,0) [0|0] "" Vector__XXX
 SG_ Module1 m0 : 8|8@1+ (1,0) [0|0] "" Vector__XXX
 SG_ Module2 m0 : 16|8@1+ (1,0) [0|0] "" Vector__XXX
 SG_ Module3 m0 : 24|8@1+ (1,0) [0|0] "" Vector__XXX
 SG_ Module4 m0 : 32|8@1+ (1,0) [0|0] "" Vector__XXX
 SG_ Module5 m1 : 8|8@1+ (1,0) [0|0] "" Vector__XXX
 SG_ Module6 m1 : 16|8@1+ (1,0) [0|0] "" Vector__XXX
 SG_ Module7 m1 : 24|8@1+ (1,0) [0|0] "" Vector__XXX
 SG_ Module8 m1 : 32|8@1+ (1,0) [0|0] "" Vector__XXX
 SG_ Module9 m2 : 8|8@1+ (1,0) [0|0] "" Vector__XXX
 SG_ Module10 m2 : 16|8@1+ (1,0) [0|0] "" Vector__XXX
 SG_ Module11 m2 : 24|8@1+ (1,0) [0|0] "" Vector__XXX
 SG_ Module12 m2 : 32|8@1+ (1,0) [0|0] "" Vector__XXX
 SG_ Module13 m3 : 8|8@1+ (1,0) [0|0] "" Vector__XXX
 SG_ Module14 m3 : 16|8@1+ (1,0) [0|0] "" Vector__XXX
 SG_ Module15 m3 : 24|8@1+ (1,0) [0|0] "" Vector__XXX
 SG_ Module16 m3 : 32|8@1+ (1,0) [0|0] "" Vector__XXX
 SG_ Module17 m4 : 8|8@1+ (1,0) [0|0] "" Vector__XXX
 SG_ Module18 m4 : 16|8@1+ (1,0) [0|0] "" Vector__XXX
 SG_ Module19 m4 : 24|8@1+ (1,0) [0|0] "" Vector__XXX
 SG_ Module20 m4 : 32|8@1+ (1,0) [0|0] "" Vector__XXX
 SG_ Module21 m5 : 8|8@1+ (1,0) [0|0] "" Vector__XXX
 SG_ Module22 m5 : 16|8@1+ (1,0) [0|0] "" Vector__XXX
 SG_ Module23 m5 : 24|8@1+ (1,0) [0|0] "" Vector__XXX
 SG_ Module24 m5 : 32|8@1+ (1,0) [0|0] "" Vector__XXX
 SG_ Module25 m6 : 8|8@1+ (1,0) [0|0] "" Vector__XXX
 SG_ Module26 m6 : 16|8@1+ (1,0) [0|0] "" Vector__XXX
 SG_ Module27 m6 : 24|8@1+ (1,0) [0|0] "" Vector__XXX
 SG_ Module28 m6 : 32|8@1+ (1,0) [0|0] "" Vector__XXX
 SG_ Module29 m7 : 8|8@1+ (1,0) [0|0] "" Vector__XXX
 SG_ Module30 m7 : 16|8@1+ (1,0) [0|0] "" Vector__XXX
 SG_ Module31 m7 : 24|8@1+ (1,0) [0|0] "" Vector__XXX
 SG_ Module32 m7 : 32|8@1+ (1,0) [0|0] "" Vector__XXX

BO_ 1577 BalancingStatus: 4 BMS
 SG_ Mod1_BalActive : 0|1@1+ (1,0) [0|1] "" Vector__XXX
 SG_ Mod2_BalActive : 1|1@1+ (1,0) [0|1] "" Vector__XXX
 SG_ Mod3_BalActive : 2|1@1+ (1,0) [0|1] "" Vector__XXX
 SG_ Mod4_BalActive : 3|1@1+ (1,0) [0|1] "" Vector__XXX
 SG_ Mod5_BalActive : 4|1@1+ (1,0) [0|1] "" Vector__XXX
 SG_ Mod6_BalActive : 5|1@1+ (1,0) [0|1] "" Vector__XXX
 SG_ Mod7_BalActive : 6|1@1+ (1,0) [0|1] "" Vector__XXX
 SG_ Mod8_BalActive : 7|1@1+ (1,0) [0|1] "" Vector__XXX
 SG_ Mod9_BalActive : 8|1@1+ (1,0) [0|1] "" Vector__XXX
 SG_ Mod10_BalActive : 9|1@1+ (1,0) [0|1] "" Vector__XXX
 SG_ Mod11_BalActive : 10|1@1+ (1,0) [0|1] "" Vector__XXX
 SG_ Mod12_BalActive : 11|1@1+ (1,0) [0|1] "" Vector__XXX
 SG_ Mod13_BalActive : 12|1@1+ (1,0) [0|1] "" Vector__XXX
 SG_ Mod14_BalActive : 13|1@1+ (1,0) [0|1] "" Vector__XXX
 SG_ Mod15_BalActive : 14|1@1+ (1,0) [0|1] "" Vector__XXX
 SG_ Mod16_BalActive : 15|1@1+ (1,0) [0|1] "" Vector__XXX
 SG_ Mod17_BalActive : 16|1@1+ (1,0) [0|1] "" Vector__XXX
 SG_ Mod18_BalActive : 17|1@1+ (1,0) [0|1] "" Vector__XXX
 SG_ Mod19_BalActive : 18|1@1+ (1,0) [0|1] "" Vector__XXX
 SG_ Mod20_BalActive : 19|1@1+ (1,0) [0|1] "" Vector__XXX
 SG_ Mod21_BalActive : 20|1@1+ (1,0) [0|1] "" Vector__XXX
 SG_ Mod22_BalActive : 21|1@1+ (1,0) [0|1] "" Vector__XXX
 SG_ Mod23_BalActive : 22|1@1+ (1,0) [0|1] "" Vector__XXX
 SG_ Mod24_BalActive : 23|1@1+ (1,0) [0|1] "" Vector__XXX
 SG_ Mod25_BalActive : 24|1@1+ (1,0) [0|1] "" Vector__XXX
 SG_ Mod26_BalActive : 25|1@1+ (1,0) [0|1] "" Vector__XXX
 SG_ Mod27_BalActive : 26|1@1+ (1,0) [0|1] "" Vector__XXX
 SG_ Mod28_BalActive : 27|1@1+ (1,0) [0|1] "" Vector__XXX
 SG_ Mod29_BalActive : 28|1@1+ (1,0) [0|1] "" Vector__XXX
 SG_ Mod30_BalActive : 29|1@1+ (1,0) [0|1] "" Vector__XXX
 SG_ Mod31_BalActive : 30|1@1+ (1,0) [0|1] "" Vector__XXX
 SG_ Mod32_BalActive : 31|1@1+ (1,0) [0|1] "" Vector__XXX

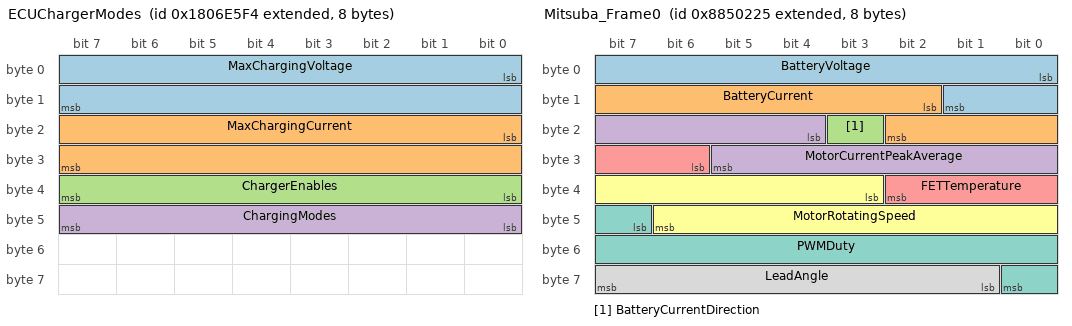
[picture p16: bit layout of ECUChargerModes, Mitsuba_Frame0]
BO_ 2550588916 ECUChargerModes: 8 ECU
 SG_ MaxChargingVoltage : 0|16@1+ (0.1,0) [0|0] "V" Vector__XXX
 SG_ MaxChargingCurrent : 16|16@1+ (0.1,0) [0|0] "A" Vector__XXX
 SG_ ChargerEnables : 32|8@1+ (1,0) [0|0] "" Vector__XXX
 SG_ ChargingModes : 40|8@1+ (1,0) [0|0] "" Vector__XXX

BO_ 2566869221 OBCStatus: 8 OBC
 SG_ OutputVoltage : 0|16@1+ (0.1,0) [0|0] "V" Vector__XXX
 SG_ OutputCurrent : 16|16@1+ (0.1,0) [0|0] "A" Vector__XXX
 SG_ HardwareProtection : 32|1@1+ (1,0) [0|0] "" Vector__XXX
 SG_ TemepratureProtection : 33|1@1+ (1,0) [0|0] "" Vector__XXX
 SG_ InputVoltageStatus : 34|2@1+ (1,0) [0|0] "" Vector__XXX
 SG_ OutputUnderVoltage : 36|1@1+ (1,0) [0|0] "" Vector__XXX
 SG_ OutputOverVoltage : 37|1@1+ (1,0) [0|0] "" Vector__XXX
 SG_ OutputOverCurrent : 38|1@1+ (1,0) [0|0] "" Vector__XXX
 SG_ OutputShortCircuit : 39|1@1+ (1,0) [0|0] "" Vector__XXX
 SG_ CommunicationStatus : 40|1@1+ (1,0) [0|0] "" Vector__XXX
 SG_ WorkingStatus : 41|2@1+ (1,0) [0|0] "" Vector__XXX
 SG_ CompletionOfInitialization : 43|1@1+ (1,0) [0|0] "" Vector__XXX
 SG_ FanEnable : 44|1@1+ (1,0) [0|0] "" Vector__XXX
 SG_ CoolingPumpFanEnable : 45|1@1+ (1,0) [0|0] "" Vector__XXX
 SG_ CCsignalStatus : 48|2@1+ (1,0) [0|0] "" Vector__XXX
 SG_ CPSignalStatus : 50|1@1+ (1,0) [0|0] "" Vector__XXX
 SG_ ChargingSocketTempFault : 51|1@1+ (1,0) [0|0] "" Vector__XXX
 SG_ ElectronicLockState : 52|3@1+ (1,0) [0|0] "" Vector__XXX
 SG_ S2SwitchControlStatus : 55|1@1+ (1,0) [0|0] "" Vector__XXX
 SG_ Temperaturre : 56|8@1+ (1,-40) [0|0] "C" Vector__XXX

BO_ 2297992512 MitsubaDataRequest: 1 MC
 SG_ RequestForFrames : 0|1@1+ (2,0) [0|0] "" Vector__XXX

BO_ 2290418213 Mitsuba_Frame0: 8 MC
 SG_ BatteryVoltage : 0|10@1+ (0.5,0) [0|0] "V" Vector__XXX
 SG_ BatteryCurrent : 10|9@1+ (1,0) [0|0] "A" Vector__XXX
 SG_ BatteryCurrentDirection : 19|1@1+ (1,0) [0|0] "" Vector__XXX
 SG_ MotorCurrentPeakAverage : 20|10@1+ (1,0) [0|0] "A" Vector__XXX
 SG_ FETTemperature : 30|5@1+ (5,0) [0|0] "C" Vector__XXX
 SG_ MotorRotatingSpeed : 35|12@1+ (0.10668848651,0) [0|0] "km/h" Vector__XXX
 SG_ PWMDuty : 47|10@1+ (0.5,0) [0|0] "%" Vector__XXX
 SG_ LeadAngle : 57|7@1+ (0.5,0) [0|0] "C" Vector__XXX

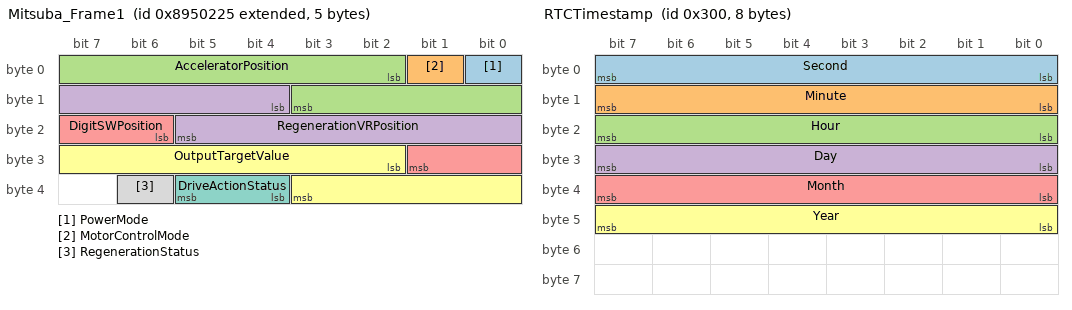
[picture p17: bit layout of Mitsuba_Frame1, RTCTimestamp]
BO_ 2291466789 Mitsuba_Frame1: 5 MC
 SG_ PowerMode : 0|1@1+ (1,0) [0|0] "" Vector__XXX
 SG_ MotorControlMode : 1|1@1+ (1,0) [0|0] "" Vector__XXX
 SG_ AcceleratorPosition : 2|10@1+ (0.5,0) [0|0] "%" Vector__XXX
 SG_ RegenerationVRPosition : 12|10@1+ (0.5,0) [0|0] "%" Vector__XXX
 SG_ DigitSWPosition : 22|4@1+ (1,0) [0|0] "" Vector__XXX
 SG_ OutputTargetValue : 26|10@1+ (0.5,0) [0|0] "A" Vector__XXX
 SG_ DriveActionStatus : 36|2@1+ (1,0) [0|0] "" Vector__XXX
 SG_ RegenerationStatus : 38|1@1+ (1,0) [0|0] "" Vector__XXX

BO_ 2292515365 Mitsuba_Frame2: 5 MC
 SG_ AnalogSensorError : 0|1@1+ (1,0) [0|0] "" Vector__XXX
 SG_ MotorCurrentSensorUError : 1|1@1+ (1,0) [0|0] "" Vector__XXX
 SG_ MotorCurrentSensorWError : 2|1@1+ (1,0) [0|0] "" Vector__XXX
 SG_ FETThermistorError : 3|1@1+ (1,0) [0|0] "" Vector__XXX
 SG_ RFU : 4|1@1+ (1,0) [0|0] "" Vector__XXX
 SG_ BatteryVoltageSensorError : 5|1@1+ (1,0) [0|0] "" Vector__XXX
 SG_ BatteryCurrentSensorError : 6|1@1+ (1,0) [0|0] "" Vector__XXX
 SG_ BatteryCurrentSensorAdjustError : 7|1@1+ (1,0) [0|0] "" Vector__XXX
 SG_ MotorCurrentSensorAdjustError : 8|1@1+ (1,0) [0|0] "" Vector__XXX
 SG_ AcceleratorPositionError : 9|1@1+ (1,0) [0|0] "" Vector__XXX
 SG_ RFU2 : 10|1@1+ (1,0) [0|0] "" Vector__XXX
 SG_ ControllerVoltageSensorError : 11|1@1+ (1,0) [0|0] "" Vector__XXX
 SG_ RFU3 : 12|4@1+ (1,0) [0|0] "" Vector__XXX
 SG_ PowerSystemError : 16|1@1+ (1,0) [0|0] "" Vector__XXX
 SG_ OverCurrentError : 17|1@1+ (1,0) [0|0] "" Vector__XXX
 SG_ RFU4 : 18|1@1+ (1,0) [0|0] "" Vector__XXX
 SG_ OverVoltageError : 19|1@1+ (1,0) [0|0] "" Vector__XXX
 SG_ RFU5 : 20|1@1+ (1,0) [0|0] "" Vector__XXX
 SG_ OverCurrentLimit : 21|1@1+ (1,0) [0|0] "" Vector__XXX
 SG_ RFU6 : 22|2@1+ (1,0) [0|0] "" Vector__XXX
 SG_ MotorSystemError : 24|1@1+ (1,0) [0|0] "" Vector__XXX
 SG_ MotorLock : 25|1@1+ (1,0) [0|0] "" Vector__XXX
 SG_ HallSensorShort : 26|1@1+ (1,0) [0|0] "" Vector__XXX
 SG_ HallSensorOpen : 27|1@1+ (1,0) [0|0] "" Vector__XXX
 SG_ RFU7 : 28|4@1+ (1,0) [0|0] "" Vector__XXX
 SG_ OverHeatLevel : 32|2@1+ (1,0) [0|0] "" Vector__XXX

BO_ 768 RTCTimestamp: 8 MEMORATOR
 SG_ Second : 0|8@1+ (1,0) [0|0] "" Vector__XXX
 SG_ Minute : 8|8@1+ (1,0) [0|0] "" Vector__XXX
 SG_ Hour : 16|8@1+ (1,0) [0|0] "" Vector__XXX
 SG_ Day : 24|8@1+ (1,0) [0|0] "" Vector__XXX
 SG_ Month : 32|8@1+ (1,0) [0|0] "" Vector__XXX
 SG_ Year : 40|8@1+ (1,0) [0|0] "" Vector__XXX

BO_ 1874 TELImuAG_X: 8 TEL
 SG_ ImuAGXAccel : 0|32@1- (1,0) [0|0] "m/s^2" Vector__XXX
 SG_ ImuAGXGyro : 32|32@1- (1,0) [0|0] "rad/s" Vector__XXX

BO_ 1875 TELImuAGY: 8 TEL
 SG_ ImuAGYAccel : 0|32@1- (1,0) [0|0] "m/s^2" Vector__XXX
 SG_ ImuAGYGyro : 32|32@1- (1,0) [0|0] "rad/s" Vector__XXX

BO_ 1876 TELImuAGZ: 8 TEL
 SG_ ImuAGZAccel : 0|32@1- (1,0) [0|0] "m/s^2" Vector__XXX
 SG_ ImuAGZGyro : 32|32@1- (1,0) [0|0] "rad/s" Vector__XXX

BO_ 1877 TELImuMX: 4 TEL
 SG_ ImuMXMag : 0|32@1- (1,0) [0|0] "uT" Vector__XXX

BO_ 1878 TELImuMY: 4 TEL
 SG_ ImuMYMag : 0|32@1- (1,0) [0|0] "uT" Vector__XXX

BO_ 1879 TELImuMZ: 4 TEL
 SG_ ImuMZMag : 0|32@1- (1,0) [0|0] "uT" Vector__XXX

BO_ 1891 CANBusLoad: 1 TEL
 SG_ BusLoad : 0|8@1+ (1,0) [0|0] "" Vector__XXX

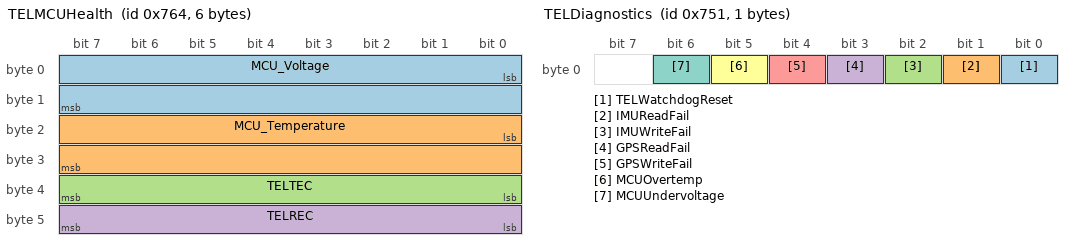
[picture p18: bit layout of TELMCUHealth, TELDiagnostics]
BO_ 1892 TELMCUHealth: 6 TEL
 SG_ MCU_Voltage : 0|16@1+ (1,0) [0|0] "mV" Vector__XXX
 SG_ MCU_Temperature : 16|16@1+ (1,0) [0|0] "Celsius" Vector__XXX
 SG_ TELTEC : 32|8@1+ (1,0) [0|255] "" Vector__XXX
 SG_ TELREC : 40|8@1+ (1,0) [0|255] "" Vector__XXX

BO_ 1872 TELTimeSinceBootup: 4 TEL
 SG_ TELTimeSinceBootUp : 0|32@1+ (1,0) [0|0] "s" Vector__XXX

BO_ 1873 TELDiagnostics: 1 TEL
 SG_ TELWatchdogReset : 0|1@1+ (1,0) [0|0] "" Vector__XXX
 SG_ IMUReadFail : 1|1@1+ (1,0) [0|0] "" Vector__XXX
 SG_ IMUWriteFail : 2|1@1+ (1,0) [0|0] "" Vector__XXX
 SG_ GPSReadFail : 3|1@1+ (1,0) [0|0] "" Vector__XXX
 SG_ GPSWriteFail : 4|1@1+ (1,0) [0|0] "" Vector__XXX
 SG_ MCUOvertemp : 5|1@1+ (1,0) [0|0] "" Vector__XXX
 SG_ MCUUndervoltage : 6|1@1+ (1,0) [0|0] "" Vector__XXX

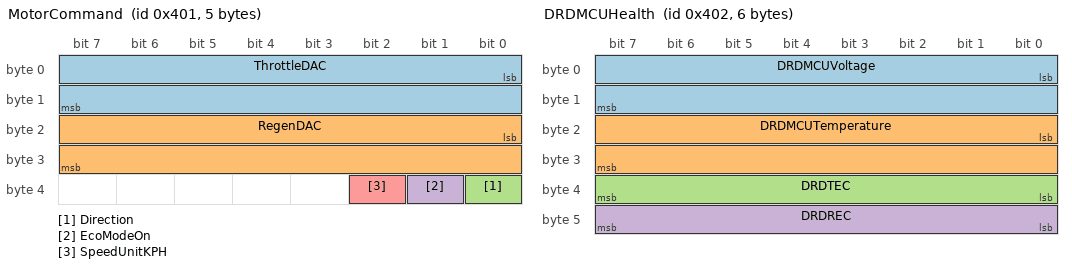
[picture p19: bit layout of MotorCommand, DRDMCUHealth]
BO_ 1025 MotorCommand: 5 DRD
 SG_ ThrottleDAC : 0|16@1+ (1,0) [0|0] "" Vector__XXX
 SG_ RegenDAC : 16|16@1+ (1,0) [0|0] "" Vector__XXX
 SG_ Direction : 32|1@1+ (1,0) [0|0] "" Vector__XXX
 SG_ EcoModeOn : 33|1@1+ (1,0) [0|0] "" Vector__XXX
 SG_ SpeedUnitKPH : 34|1@1+ (1,0) [0|0] "" Vector__XXX

BO_ 1026 DRDMCUHealth: 6 DRD
 SG_ DRDMCUVoltage : 0|16@1+ (1,0) [0|65535] "mV" Vector__XXX
 SG_ DRDMCUTemperature : 16|16@1- (1,0) [-40|125] "degC" Vector__XXX
 SG_ DRDTEC : 32|8@1+ (1,0) [0|255] "" Vector__XXX
 SG_ DRDREC : 40|8@1+ (1,0) [0|255] "" Vector__XXX

BO_ 1027 DRDDiagnostics: 8 DRD
 SG_ RawADC1 : 0|16@1+ (1,0) [0|0] "" Vector__XXX
 SG_ RawADC2 : 16|16@1+ (1,0) [0|0] "" Vector__XXX
 SG_ BrakePressed : 32|1@1+ (1,0) [0|0] "" Vector__XXX
 SG_ RegenEnabled : 33|1@1+ (1,0) [0|0] "" Vector__XXX
 SG_ ADCOutOfRange : 34|1@1+ (1,0) [0|0] "" Vector__XXX
 SG_ ADCMismatch : 35|1@1+ (1,0) [0|0] "" Vector__XXX
 SG_ DRDWatchdogReset : 36|1@1+ (1,0) [0|0] "" Vector__XXX
 SG_ MotorCommFault : 37|1@1+ (1,0) [0|0] "" Vector__XXX
 SG_ DRDMCUOverTemp : 38|1@1+ (1,0) [0|1] "" Vector__XXX
 SG_ DRDMCUUnderVoltage : 39|1@1+ (1,0) [0|1] "" Vector__XXX
 SG_ DriveState : 40|8@1+ (1,0) [0|0] "" Vector__XXX
 SG_ SpeedTimeout : 48|1@1+ (1,0) [0|0] "" Vector__XXX
 SG_ DriveStateTimeout : 49|1@1+ (1,0) [0|0] "" Vector__XXX
 SG_ SOCTimeout : 50|1@1+ (1,0) [0|0] "" Vector__XXX
 SG_ VoltageTimeout : 51|1@1+ (1,0) [0|0] "" Vector__XXX
 SG_ CurrentTimeout : 52|1@1+ (1,0) [0|0] "" Vector__XXX
 SG_ AccelTimeout : 53|1@1+ (1,0) [0|0] "" Vector__XXX
 SG_ SOC : 56|8@1+ (1,0) [0|0] "%" Vector__XXX

BO_ 1026 DRDMCUHealth: 4 DRD
 SG_ DRDMCUSupplyVoltage : 0|16@1+ (1,0) [0|4000] "mV" Vector__XXX
 SG_ DRDMCUTemperature : 16|16@1- (1,0) [-40|125] "degC" Vector__XXX

BO_ 1028 DRDTimeSinceBootup: 4 DRD
 SG_ DRDTimeSinceBootUp : 0|32@1+ (1,0) [0|0] "" Vector__XXX

//////////////////////////////////////////////////////////////////////
// MPPT Input Measurements (0x6A0/0x6B0/0x6C0/0x6D0)
//////////////////////////////////////////////////////////////////////
BO_ 1696 MPPTInputMeasurementsA: 8 MPPT
 SG_ InputVoltageA       :  0|32@1- (1,0) [0|0] "V"  MPPT
 SG_ InputCurrentA       : 32|32@1- (1,0) [0|0] "A"  MPPT

BO_ 1712 MPPTInputMeasurementsB: 8 MPPT
 SG_ InputVoltageB       :  0|32@1- (1,0) [0|0] "V"  MPPT
 SG_ InputCurrentB       : 32|32@1- (1,0) [0|0] "A"  MPPT

BO_ 1728 MPPTInputMeasurementsC: 8 MPPT
 SG_ InputVoltageC       :  0|32@1- (1,0) [0|0] "V"  MPPT
 SG_ InputCurrentC       : 32|32@1- (1,0) [0|0] "A"  MPPT

BO_ 1744 MPPTInputMeasurementsD: 8 MPPT
 SG_ InputVoltageD       :  0|32@1- (1,0) [0|0] "V"  MPPT
 SG_ InputCurrentD       : 32|32@1- (1,0) [0|0] "A"  MPPT

//////////////////////////////////////////////////////////////////////
// MPPT Output Measurements (0x6A1/0x6B1/0x6C1/0x6D1)
//////////////////////////////////////////////////////////////////////
BO_ 1697 MPPTOutputMeasurementsA: 8 MPPT
 SG_ OutputVoltageA      :  0|32@1- (1,0) [0|0] "V"  MPPT
 SG_ OutputCurrentA      : 32|32@1- (1,0) [0|0] "A"  MPPT

BO_ 1713 MPPTOutputMeasurementsB: 8 MPPT
 SG_ OutputVoltageB      :  0|32@1- (1,0) [0|0] "V"  MPPT
 SG_ OutputCurrentB      : 32|32@1- (1,0) [0|0] "A"  MPPT

BO_ 1729 MPPTOutputMeasurementsC: 8 MPPT
 SG_ OutputVoltageC      :  0|32@1- (1,0) [0|0] "V"  MPPT
 SG_ OutputCurrentC      : 32|32@1- (1,0) [0|0] "A"  MPPT

BO_ 1745 MPPTOutputMeasurementsD: 8 MPPT
 SG_ OutputVoltageD      :  0|32@1- (1,0) [0|0] "V"  MPPT
 SG_ OutputCurrentD      : 32|32@1- (1,0) [0|0] "A"  MPPT

//////////////////////////////////////////////////////////////////////
// MPPT Temperatures (0x6A2/0x6B2/0x6C2/0x6D2)
//////////////////////////////////////////////////////////////////////
BO_ 1698 MPPTTemperatureA : 8 MPPT
 SG_ MosfetTemperatureA     :   0|32@1- (1,0) [-40|150] "°C" MPPT
 SG_ ControllerTemperatureA :   32|32@1- (1,0) [-40|150] "°C" MPPT

BO_ 1714 MPPTTemperatureB: 8 MPPT
 SG_ MosfetTemperatureB     :   0|32@1- (1,0) [-40|150] "°C" MPPT
 SG_ ControllerTemperatureB :   32|32@1- (1,0) [-40|150] "°C" MPPT

BO_ 1730 MPPTTemperatureC: 8 MPPT
 SG_ MosfetTemperatureC     :   0|32@1- (1,0) [-40|150] "°C" MPPT
 SG_ ControllerTemperatureC :   32|32@1- (1,0) [-40|150] "°C" MPPT

BO_ 1746 MPPTTemperatureD: 8 MPPT
 SG_ MosfetTemperatureD     :   0|32@1- (1,0) [-40|150] "°C" MPPT
 SG_ ControllerTemperatureD :   32|32@1- (1,0) [-40|150] "°C" MPPT

//////////////////////////////////////////////////////////////////////
// MPPT Auxiliary Power Supply (0x6A3/0x6B3/0x6C3/0x6D3)
//////////////////////////////////////////////////////////////////////
BO_ 1699 MPPTAuxiliaryPowerSupplyA: 8 MPPT
 SG_ Aux12VA             :  0|32@1- (1,0) [0|20]  "V"  MPPT
 SG_ Aux3VA              : 32|32@1- (1,0) [0|5]   "V"  MPPT

BO_ 1715 MPPTAuxiliaryPowerSupplyB: 8 MPPT
 SG_ Aux12VB             :  0|32@1- (1,0) [0|20]  "V"  MPPT
 SG_ Aux3VB              : 32|32@1- (1,0) [0|5]   "V"  MPPT

BO_ 1731 MPPTAuxiliaryPowerSupplyC: 8 MPPT
 SG_ Aux12VC             :  0|32@1- (1,0) [0|20]  "V"  MPPT
 SG_ Aux3VC              : 32|32@1- (1,0) [0|5]   "V"  MPPT

BO_ 1747 MPPTAuxiliaryPowerSupplyD: 8 MPPT
 SG_ Aux12VD             :  0|32@1- (1,0) [0|20]  "V"  MPPT
 SG_ Aux3VD              : 32|32@1- (1,0) [0|5]   "V"  MPPT

//////////////////////////////////////////////////////////////////////
// MPPT Limits (0x6A4/0x6B4/0x6C4/0x6D4)
//////////////////////////////////////////////////////////////////////
BO_ 1700 MPPTLimitsA: 8 MPPT
 SG_ MaxOutputVoltageLimitA:  0|32@1- (1,0) [0|0] "V" MPPT
 SG_ MaxInputCurrentLimitA : 32|32@1- (1,0) [0|0] "A" MPPT

BO_ 1716 MPPTLimitsB: 8 MPPT
 SG_ MaxOutputVoltageLimitB:  0|32@1- (1,0) [0|0] "V" MPPT
 SG_ MaxInputCurrentLimitB : 32|32@1- (1,0) [0|0] "A" MPPT

BO_ 1732 MPPTLimitsC: 8 MPPT
 SG_ MaxOutputVoltageLimitC:  0|32@1- (1,0) [0|0] "V" MPPT
 SG_ MaxInputCurrentLimitC : 32|32@1- (1,0) [0|0] "A" MPPT

BO_ 1748 MPPTLimitsD: 8 MPPT
 SG_ MaxOutputVoltageLimitD:  0|32@1- (1,0) [0|0] "V" MPPT
 SG_ MaxInputCurrentLimitD : 32|32@1- (1,0) [0|0] "A" MPPT

//////////////////////////////////////////////////////////////////////
// MPPT Status (0x6A5/0x6B5/0x6C5/0x6D5)
//////////////////////////////////////////////////////////////////////
BO_ 1701 MPPTStatusA: 8 MPPT
 SG_ CANRXErrorCounterA    :  0| 8@1+ (1,0) [0|255] "" MPPT
 SG_ CANTXErrorCounterA    :  8| 8@1+ (1,0) [0|255] "" MPPT
 SG_ CANTXOverflowCounterA : 16| 8@1+ (1,0) [0|255] "" MPPT
 SG_ HWOvervoltageA        : 24| 1@1+ (1,0) [0|1]   "" MPPT
 SG_ HWOvercurrentA        : 25| 1@1+ (1,0) [0|1]   "" MPPT
 SG_ Reserved1A            : 26| 1@1+ (1,0) [0|1]   "" MPPT
 SG_ Undervoltage12VA      : 27| 1@1+ (1,0) [0|1]   "" MPPT
 SG_ BatteryFullA          : 28| 1@1+ (1,0) [0|1]   "" MPPT
 SG_ BatteryLowA           : 29| 1@1+ (1,0) [0|1]   "" MPPT
 SG_ MosfetOverheatA       : 30| 1@1+ (1,0) [0|1]   "" MPPT
 SG_ LowArrayPowerA        : 31| 1@1+ (1,0) [0|1]   "" MPPT
 SG_ GlobalMPPTA           : 32| 1@1+ (1,0) [0|1]   "" MPPT
 SG_ LocalMPPTA            : 33| 1@1+ (1,0) [0|1]   "" MPPT
 SG_ DutyCycleMaxA         : 34| 1@1+ (1,0) [0|1]   "" MPPT
 SG_ DutyCycleMinA         : 35| 1@1+ (1,0) [0|1]   "" MPPT
 SG_ MosfetTempFaultA      : 36| 1@1+ (1,0) [0|1]   "" MPPT
 SG_ OutputVoltageMaxA     : 37| 1@1+ (1,0) [0|1]   "" MPPT
 SG_ InputCurrentMaxA      : 38| 1@1+ (1,0) [0|1]   "" MPPT
 SG_ InputCurrentMinA      : 39| 1@1+ (1,0) [0|1]   "" MPPT
 SG_ ModeA                 : 40| 8@1+ (1,0) [0|1]   "" MPPT
 SG_ Reserved2A            : 48| 8@1+ (1,0) [0|255] "" MPPT
 SG_ TestCounterA          : 56| 8@1+ (1,0) [0|255] "" MPPT

BO_ 1717 MPPTStatusB: 8 MPPT
 SG_ CANRXErrorCounterB    :  0| 8@1+ (1,0) [0|255] "" MPPT
 SG_ CANTXErrorCounterB    :  8| 8@1+ (1,0) [0|255] "" MPPT
 SG_ CANTXOverflowCounterB : 16| 8@1+ (1,0) [0|255] "" MPPT
 SG_ HWOvervoltageB        : 24| 1@1+ (1,0) [0|1]   "" MPPT
 SG_ HWOvercurrentB        : 25| 1@1+ (1,0) [0|1]   "" MPPT
 SG_ Reserved1B            : 26| 1@1+ (1,0) [0|1]   "" MPPT
 SG_ Undervoltage12VB      : 27| 1@1+ (1,0) [0|1]   "" MPPT
 SG_ BatteryFullB          : 28| 1@1+ (1,0) [0|1]   "" MPPT
 SG_ BatteryLowB           : 29| 1@1+ (1,0) [0|1]   "" MPPT
 SG_ MosfetOverheatB       : 30| 1@1+ (1,0) [0|1]   "" MPPT
 SG_ LowArrayPowerB        : 31| 1@1+ (1,0) [0|1]   "" MPPT
 SG_ GlobalMPPTB           : 32| 1@1+ (1,0) [0|1]   "" MPPT
 SG_ LocalMPPTB            : 33| 1@1+ (1,0) [0|1]   "" MPPT
 SG_ DutyCycleMaxB         : 34| 1@1+ (1,0) [0|1]   "" MPPT
 SG_ DutyCycleMinB         : 35| 1@1+ (1,0) [0|1]   "" MPPT
 SG_ MosfetTempFaultB      : 36| 1@1+ (1,0) [0|1]   "" MPPT
 SG_ OutputVoltageMaxB     : 37| 1@1+ (1,0) [0|1]   "" MPPT
 SG_ InputCurrentMaxB      : 38| 1@1+ (1,0) [0|1]   "" MPPT
 SG_ InputCurrentMinB      : 39| 1@1+ (1,0) [0|1]   "" MPPT
 SG_ ModeB                 : 40| 8@1+ (1,0) [0|1]   "" MPPT
 SG_ Reserved2B            : 48| 8@1+ (1,0) [0|255] "" MPPT
 SG_ TestCounterB          : 56| 8@1+ (1,0) [0|255] "" MPPT

BO_ 1733 MPPTStatusC: 8 MPPT
 SG_ CANRXErrorCounterC    :  0| 8@1+ (1,0) [0|255] "" MPPT
 SG_ CANTXErrorCounterC    :  8| 8@1+ (1,0) [0|255] "" MPPT
 SG_ CANTXOverflowCounterC : 16| 8@1+ (1,0) [0|255] "" MPPT
 SG_ HWOvervoltageC        : 24| 1@1+ (1,0) [0|1]   "" MPPT
 SG_ HWOvercurrentC        : 25| 1@1+ (1,0) [0|1]   "" MPPT
 SG_ Reserved1C            : 26| 1@1+ (1,0) [0|1]   "" MPPT
 SG_ Undervoltage12VC      : 27| 1@1+ (1,0) [0|1]   "" MPPT
 SG_ BatteryFullC          : 28| 1@1+ (1,0) [0|1]   "" MPPT
 SG_ BatteryLowC           : 29| 1@1+ (1,0) [0|1]   "" MPPT
 SG_ MosfetOverheatC       : 30| 1@1+ (1,0) [0|1]   "" MPPT
 SG_ LowArrayPowerC        : 31| 1@1+ (1,0) [0|1]   "" MPPT
 SG_ GlobalMPPTC           : 32| 1@1+ (1,0) [0|1]   "" MPPT
 SG_ LocalMPPTC            : 33| 1@1+ (1,0) [0|1]   "" MPPT
 SG_ DutyCycleMaxC         : 34| 1@1+ (1,0) [0|1]   "" MPPT
 SG_ DutyCycleMinC         : 35| 1@1+ (1,0) [0|1]   "" MPPT
 SG_ MosfetTempFaultC      : 36| 1@1+ (1,0) [0|1]   "" MPPT
 SG_ OutputVoltageMaxC     : 37| 1@1+ (1,0) [0|1]   "" MPPT
 SG_ InputCurrentMaxC      : 38| 1@1+ (1,0) [0|1]   "" MPPT
 SG_ InputCurrentMinC      : 39| 1@1+ (1,0) [0|1]   "" MPPT
 SG_ ModeC                 : 40| 8@1+ (1,0) [0|1]   "" MPPT
 SG_ Reserved2C            : 48| 8@1+ (1,0) [0|255] "" MPPT
 SG_ TestCounterC          : 56| 8@1+ (1,0) [0|255] "" MPPT

BO_ 1749 MPPTStatusD: 8 MPPT
 SG_ CANRXErrorCounterD    :  0| 8@1+ (1,0) [0|255] "" MPPT
 SG_ CANTXErrorCounterD    :  8| 8@1+ (1,0) [0|255] "" MPPT
 SG_ CANTXOverflowCounterD : 16| 8@1+ (1,0) [0|255] "" MPPT
 SG_ HWOvervoltageD        : 24| 1@1+ (1,0) [0|1]   "" MPPT
 SG_ HWOvercurrentD        : 25| 1@1+ (1,0) [0|1]   "" MPPT
 SG_ Reserved1D            : 26| 1@1+ (1,0) [0|1]   "" MPPT
 SG_ Undervoltage12VD      : 27| 1@1+ (1,0) [0|1]   "" MPPT
 SG_ BatteryFullD          : 28| 1@1+ (1,0) [0|1]   "" MPPT
 SG_ BatteryLowD           : 29| 1@1+ (1,0) [0|1]   "" MPPT
 SG_ MosfetOverheatD       : 30| 1@1+ (1,0) [0|1]   "" MPPT
 SG_ LowArrayPowerD        : 31| 1@1+ (1,0) [0|1]   "" MPPT
 SG_ GlobalMPPTD           : 32| 1@1+ (1,0) [0|1]   "" MPPT
 SG_ LocalMPPTD            : 33| 1@1+ (1,0) [0|1]   "" MPPT
 SG_ DutyCycleMaxD         : 34| 1@1+ (1,0) [0|1]   "" MPPT
 SG_ DutyCycleMinD         : 35| 1@1+ (1,0) [0|1]   "" MPPT
 SG_ MosfetTempFaultD      : 36| 1@1+ (1,0) [0|1]   "" MPPT
 SG_ OutputVoltageMaxD     : 37| 1@1+ (1,0) [0|1]   "" MPPT
 SG_ InputCurrentMaxD      : 38| 1@1+ (1,0) [0|1]   "" MPPT
 SG_ InputCurrentMinD      : 39| 1@1+ (1,0) [0|1]   "" MPPT
 SG_ ModeD                 : 40| 8@1+ (1,0) [0|1]   "" MPPT
 SG_ Reserved2D            : 48| 8@1+ (1,0) [0|255] "" MPPT
 SG_ TestCounterD          : 56| 8@1+ (1,0) [0|255] "" MPPT

//////////////////////////////////////////////////////////////////////
// MPPT Power Connector (0x6A6/0x6B6/0x6C6/0x6D6)
//////////////////////////////////////////////////////////////////////
BO_ 1702 MPPTPowerConnectorA: 8 MPPT
 SG_ OutputVoltageBattSideA:  0|32@1- (1,0) [0|0] "V"  MPPT
 SG_ ConnectorTemperatureA : 32|32@1- (1,0) [-40|150] "°C" MPPT

BO_ 1718 MPPTPowerConnectorB: 8 MPPT
 SG_ OutputVoltageBattSideB:  0|32@1- (1,0) [0|0] "V"  MPPT
 SG_ ConnectorTemperatureB : 32|32@1- (1,0) [-40|150] "°C" MPPT

BO_ 1734 MPPTPowerConnectorC: 8 MPPT
 SG_ OutputVoltageBattSideC:  0|32@1- (1,0) [0|0] "V"  MPPT
 SG_ ConnectorTemperatureC : 32|32@1- (1,0) [-40|150] "°C" MPPT

BO_ 1750 MPPTPowerConnectorD: 8 MPPT
 SG_ OutputVoltageBattSideD:  0|32@1- (1,0) [0|0] "V"  MPPT
 SG_ ConnectorTemperatureD : 32|32@1- (1,0) [-40|150] "°C" MPPT

//////////////////////////////////////////////////////////////////////
// MPPT Mode Command (0x6A8/0x6B8/0x6C8/0x6D8)
//////////////////////////////////////////////////////////////////////
BO_ 1704 MPPTModeCommandA: 1 MPPT
 SG_ ModeCmdA             :  0| 8@1+ (1,0) [0|1] "" MPPT

BO_ 1720 MPPTModeCommandB: 1 MPPT
 SG_ ModeCmdB             :  0| 8@1+ (1,0) [0|1] "" MPPT

BO_ 1736 MPPTModeCommandC: 1 MPPT
 SG_ ModeCmdC             :  0| 8@1+ (1,0) [0|1] "" MPPT

BO_ 1752 MPPTModeCommandD: 1 MPPT
 SG_ ModeCmdD             :  0| 8@1+ (1,0) [0|1] "" MPPT

//////////////////////////////////////////////////////////////////////
// MPPT Max Output Voltage Command (0x6AA/0x6BA/0x6CA/0x6DA)
//////////////////////////////////////////////////////////////////////
BO_ 1706 MPPTMaxOutputVoltageCommandA: 4 MPPT
 SG_ MaxOutputVoltageCmdA :  0|32@1- (1,0) [0|0] "V" MPPT

BO_ 1722 MPPTMaxOutputVoltageCommandB: 4 MPPT
 SG_ MaxOutputVoltageCmdB :  0|32@1- (1,0) [0|0] "V" MPPT

BO_ 1738 MPPTMaxOutputVoltageCommandC: 4 MPPT
 SG_ MaxOutputVoltageCmdC :  0|32@1- (1,0) [0|0] "V" MPPT

BO_ 1754 MPPTMaxOutputVoltageCommandD: 4 MPPT
 SG_ MaxOutputVoltageCmdD :  0|32@1- (1,0) [0|0] "V" MPPT

//////////////////////////////////////////////////////////////////////
// MPPT Max Output Current Command (0x6AB/0x6BB/0x6CB/0x6DB)
//////////////////////////////////////////////////////////////////////
BO_ 1707 MPPTMaxOutputCurrentCommandA: 4 MPPT
 SG_ MaxOutputCurrentCmdA :  0|32@1- (1,0) [0|0] "A" MPPT

BO_ 1723 MPPTMaxOutputCurrentCommandB: 4 MPPT
 SG_ MaxOutputCurrentCmdB :  0|32@1- (1,0) [0|0] "A" MPPT

BO_ 1739 MPPTMaxOutputCurrentCommandC: 4 MPPT
 SG_ MaxOutputCurrentCmdC :  0|32@1- (1,0) [0|0] "A" MPPT

BO_ 1755 MPPTMaxOutputCurrentCommandD: 4 MPPT
 SG_ MaxOutputCurrentCmdD :  0|32@1- (1,0) [0|0] "A" MPPT

CM_ BO_ 929 "Sent every 200 ms in all states. All zero until DIST enters FAULT, then holds the causes latched on FAULT entry until reset.";
CM_ SG_ 1572 b0x00 "Unused";
CM_ SG_ 1572 SOH "Unused";
CM_ SG_ 1573 AverageTemp "Twos Complement";
CM_ SG_ 1573 MinTemp "Twos Complement
";
CM_ SG_ 1573 MaxTemp "Twos Complement";
CM_ SG_ 1575 Temp1 "Twos Complement";
CM_ SG_ 1575 Temp2 "Twos Complement";
CM_ SG_ 1575 Temp3 "Twos Complement";
CM_ SG_ 1575 Temp4 "Twos Complement";
CM_ SG_ 1575 Temp5 "Twos Complement";
CM_ SG_ 1575 Temp6 "Twos Complement";
CM_ SG_ 1575 Temp7 "Twos Complement";
CM_ SG_ 1575 Temp8 "Twos Complement";
CM_ SG_ 1575 Temp9 "Twos Complement";
CM_ SG_ 1575 Temp10 "Twos Complement";
CM_ SG_ 1575 Temp11 "Twos Complement";
CM_ SG_ 1575 Temp12 "Twos Complement";
CM_ SG_ 1575 Temp13 "Twos Complement";
CM_ SG_ 1575 Temp14 "Twos Complement";
CM_ SG_ 1575 Temp15 "Twos Complement";
CM_ SG_ 1575 Temp16 "Twos Complement";
CM_ SG_ 1575 Temp17 "Twos Complement";
CM_ SG_ 1575 Temp18 "Twos Complement";
CM_ SG_ 1575 Temp19 "Twos Complement";
CM_ SG_ 1575 Temp20 "Twos Complement";
CM_ SG_ 1575 Temp21 "Twos Complement";
CM_ SG_ 1575 Temp22 "Twos Complement";
CM_ SG_ 1575 Temp23 "Twos Complement";
CM_ SG_ 1575 Temp24 "Twos Complement";
CM_ SG_ 1575 Temp25 "Twos Complement";
CM_ SG_ 1575 Temp26 "Twos Complement";
CM_ SG_ 1575 Temp27 "Twos Complement";
CM_ SG_ 1575 Temp28 "Twos Complement";
CM_ SG_ 1575 Temp29 "Twos Complement";
CM_ SG_ 1575 Temp30 "Twos Complement
";
CM_ SG_ 1575 Temp31 "Twos Complement";
CM_ SG_ 1575 Temp32 "Twos Complement";
CM_ SG_ 1104 PackCurrentOld "int16_t, positive is discharging from PACK(divide by 65.535 to get value in A) Must cast back to int16_t if retrieving value from CAN bus";
CM_ SG_ 1104 LVCurrent "Unsigned, 0-30A (divide by 8.5 to get value in A)


";
CM_ SG_ 1104 SuppBattVoltage "
uint16_t, divide by 1000 to get V";
CM_ SG_ 1104 PackOverDischargeWarning "Active High
";
CM_ SG_ 1104 PackOverChargeWarning "Active High
";
CM_ SG_ 1104 DOC "Discharge overcurrent
";
CM_ SG_ 1104 COC "Charge overcurrent
";
CM_ SG_ 1104 ESTOP_Pressed "Active High
";
CM_ SG_ 1104 ResetFromWatchdog "Active High

";
CM_ SG_ 1104 VicorHeatSinkTemp "int8_t -127 to 127ï¿½C";
CM_ SG_ 2550588916 ChargerEnables "0x00: Start charger
0x01: Close output of charger
0x02: Stop charging (sleep mode)
Other values: Unused";
CM_ SG_ 2550588916 ChargingModes "0x00: charging mode
0x01: Heating mode(charger heats the heating film inside the battery, the charger does not need to detect the output voltage to work. When designing the resistance value of the heating film, it should be noted that the working voltage of the heating film must be between the MIN voltage and the MAX voltage of the battery. Preferably close to the battery's maximum voltage. It is best to turn off the output before switching modes)
Other values: Unused";
CM_ SG_ 2566869221 HardwareProtection "0: Normal, 1: Hardware Protection";
CM_ SG_ 2566869221 TemepratureProtection "0: Normal, 1: Internal Temp. Protection";
CM_ SG_ 2566869221 InputVoltageStatus "0: Normal, 1: Input under voltage, 2: Input over voltage, 3: No Input Voltage";
CM_ SG_ 2566869221 OutputUnderVoltage "0: Normal, 1: Fault";
CM_ SG_ 2566869221 OutputOverVoltage "0: Normal, 1: Fault";
CM_ SG_ 2566869221 OutputOverCurrent "0: Normal, 1: Fault";
CM_ SG_ 2566869221 OutputShortCircuit "0: Normal, 1: Fault";
CM_ SG_ 2566869221 CommunicationStatus "0: Communication is normal 1: Receive communication timeout";
CM_ SG_ 2566869221 WorkingStatus "0: Undefined, 1: work, 2: Stop, 3: Stop or standby";
CM_ SG_ 2566869221 CompletionOfInitialization "0: Not Complete, 1: Complete";
CM_ SG_ 2566869221 FanEnable "0: Close, 1: Open";
CM_ SG_ 2566869221 CoolingPumpFanEnable "0: Close, 1: Open";
CM_ SG_ 2566869221 CCsignalStatus "CC: Resistance value inside charger gun, 1.5k ohms = max 8A, 680 ohms = 16A, 220 ohms = 32A

0: Not Connected, 1: Half Connected, 2: Normally Connected, 3: Resistance detection error";
CM_ SG_ 2566869221 CPSignalStatus "CP: Power supply capacity depending on duty cycle

0: No CP signal detected, 1: CP signal normal";
CM_ SG_ 2566869221 ChargingSocketTempFault "0: Normal, 1: Overheating

Overheating fault occurs when temp is > 90 degrees
 and >15 min or if temp is >120 degrees";
CM_ SG_ 2566869221 ElectronicLockState "0: in Judgment, 1: Locked, 2: Unlocked, 3: Unlock fault, 4: Locked fault";
CM_ SG_ 2566869221 S2SwitchControlStatus "0: Switch off, 1: Closed";
CM_ SG_ 2297992512 RequestForFrames "(0000 0111) is all the frames. Comes from MDI to mitsuba motor controller";
CM_ SG_ 2290418213 BatteryVoltage "0.5V/LSB";
CM_ SG_ 2290418213 BatteryCurrent "1A/LSB";
CM_ SG_ 2290418213 BatteryCurrentDirection "0:positive current. 1:negative ";
CM_ SG_ 2290418213 MotorCurrentPeakAverage "1A/LSB";
CM_ SG_ 2290418213 FETTemperature "5deg (C)/LSB";
CM_ SG_ 2290418213 MotorRotatingSpeed "1kmh/LSB";
CM_ SG_ 2290418213 PWMDuty "0.5%/LSB (only in PWM control mode)";
CM_ SG_ 2290418213 LeadAngle "0.5deg/LSB (electric lead angle)";
CM_ SG_ 2291466789 PowerMode "0: Eco Mode. 1: Power Mode";
CM_ SG_ 2291466789 MotorControlMode "0: Current Mode. 1: PWM Mode";
CM_ SG_ 2291466789 AcceleratorPosition "0.5%/LSB";
CM_ SG_ 2291466789 RegenerationVRPosition "0.5%/LSB";
CM_ SG_ 2291466789 OutputTargetValue "0.5A/LSB (Current mode)";
CM_ SG_ 2291466789 DriveActionStatus "0: Stop. 1: RFU. 2: Forward Drive. 3: Reverse Drive";
CM_ SG_ 2291466789 RegenerationStatus "0: Drive. 1: Regeneration";
CM_ SG_ 2292515365 AnalogSensorError "AD sensor error";
CM_ SG_ 2292515365 MotorCurrentSensorUError "U phase sensor problem";
CM_ SG_ 2292515365 MotorCurrentSensorWError "W phase sensor problem";
CM_ SG_ 2292515365 FETThermistorError "controller Temp sensor error";
CM_ SG_ 2292515365 BatteryCurrentSensorError "battery current sensor ZERO(reference) position error";
CM_ SG_ 2292515365 BatteryCurrentSensorAdjustError "motor current ZERO(reference) position error";
CM_ SG_ 2292515365 ControllerVoltageSensorError "12V line voltage senor error";
CM_ SG_ 2292515365 PowerSystemError "power line error";
CM_ SG_ 2292515365 MotorLock "motor locked and no rotation";
CM_ SG_ 1808 ShockTravel1 "uint16_t";
CM_ SG_ 1808 ShockTravel2 "uint16_t";
CM_ SG_ 1808 ShockTravel3 "uint16_t";
CM_ SG_ 1808 ShockTravel4 "uint16_t";
CM_ SG_ 1809 BrakePressure1 "uint16_t, PSI";
CM_ SG_ 1809 BrakePressure2 "uint16_t, PSI";
CM_ SG_ 1809 BrakePressure3 "uint16_t, PSI";
CM_ SG_ 1809 SteeringAngle "uint16_t, Angle in Degrees";
CM_ SG_ 1810 DMAStatus "Determine if 1 bit or 1 for each channel";
CM_ SG_ 1295 MCBDriveCmdTimeout "0 = no timeout, 1 = timeout";
CM_ SG_ 1295 DirectionSentToMC "0 = reverse, 1 = forward";
CM_ SG_ 1295 DriveModeToMC "0 = ECO mode, 1 = POWER mode";
CM_ SG_ 1295 RegenSentToMC "0 = no regen requested, 1 = regen ON";
CM_ SG_ 1281 MDIWatchdogReset "1 = fault: watchdog crash / IWDG reset";
CM_ SG_ 1281 MDIOverVoltage "1 = fault: MDI voltage over threshold";
CM_ SG_ 1281 MDIMotorOverTemp "1 = fault: sets at >=100C, clears at <=95C";
CM_ SG_ 1281 MDIRTDFault "1 = RTD fault latched: +1 per faulted read, -1 per clean read, sets at 5, clears at 0";
CM_ SG_ 1281 MDIRTDCommError "1 = SPI error, or MAX31865 missing/reset";
CM_ SG_ 1281 MDITEC "CAN transmit error counter (TEC) read from the CAN peripheral. +8 per failed transmit, -1 per successful one. 0 = healthy, >127 = error passive, >255 = bus-off. A lone node with no ACK sits at 128.";
CM_ SG_ 1281 MDIREC "CAN receive error counter (REC) read from the CAN peripheral. +1 per receive error, -1 per good frame. 0 = healthy, >127 = error passive.";
CM_ SG_ 1282 RTDReadSuccess "1 = valid read, 0 = fault/HAL error";
CM_ SG_ 1282 RTDFaultFlags "0x80 = RTD high, 0x40 = RTD low, 0x04 = OV/UV, 0 = none";
CM_ SG_ 1283 MCUVoltage "0 = read failed";
CM_ SG_ 1425 STRMCUVoltage "0 = read failed";
CM_ SG_ 1425 STRMCUTemperature "int16_t, signed, degC";
CM_ SG_ 1425 STRTEC "CAN transmit error counter (TEC) read from the CAN peripheral. +8 per failed transmit, -1 per successful one. 0 = healthy, >127 = error passive, >255 = bus-off. A lone node with no ACK sits at 128.";
CM_ SG_ 1425 STRREC "CAN receive error counter (REC) read from the CAN peripheral. +1 per receive error, -1 per good frame. 0 = healthy, >127 = error passive.";
CM_ SG_ 1426 STRMCUOverTemp "1 = fault: STR MCU over temperature";
CM_ SG_ 1426 STRMCUUnderVoltage "1 = fault: STR MCU under voltage";
CM_ SG_ 1026 DRDTEC "CAN transmit error counter (TEC) read from the CAN peripheral. +8 per failed transmit, -1 per successful one. 0 = healthy, >127 = error passive, >255 = bus-off. A lone node with no ACK sits at 128.";
CM_ SG_ 1026 DRDREC "CAN receive error counter (REC) read from the CAN peripheral. +1 per receive error, -1 per good frame. 0 = healthy, >127 = error passive.";
CM_ SG_ 1892 TELTEC "CAN transmit error counter (TEC) read from the CAN peripheral. +8 per failed transmit, -1 per successful one. 0 = healthy, >127 = error passive, >255 = bus-off. A lone node with no ACK sits at 128.";
CM_ SG_ 1892 TELREC "CAN receive error counter (REC) read from the CAN peripheral. +1 per receive error, -1 per good frame. 0 = healthy, >127 = error passive.";
CM_ SG_ 1026 DRDMCUSupplyVoltage "0 = read failed";
CM_ SG_ 1026 DRDMCUTemperature "int16_t, signed, degC";
CM_ SG_ 1027 DRDMCUOverTemp "1 = fault: DRD MCU over temperature";
CM_ SG_ 1027 DRDMCUUnderVoltage "1 = fault: DRD MCU under voltage";
BA_DEF_  "BusType" STRING ;
BA_DEF_DEF_  "BusType" "CAN";
SIG_VALTYPE_ 1793 VoltSensor1 : 1;
SIG_VALTYPE_ 1793 VoltSensor2 : 1;
SIG_VALTYPE_ 1794 CurrentSensor1 : 1;
SIG_VALTYPE_ 1794 CurrentSensor2 : 1;
SIG_VALTYPE_ 1874 ImuAGXAccel : 1;
SIG_VALTYPE_ 1874 ImuAGXGyro : 1;
SIG_VALTYPE_ 1875 ImuAGYAccel : 1;
SIG_VALTYPE_ 1875 ImuAGYGyro : 1;
SIG_VALTYPE_ 1876 ImuAGZAccel : 1;
SIG_VALTYPE_ 1876 ImuAGZGyro : 1;
SIG_VALTYPE_ 1877 ImuMXMag : 1;
SIG_VALTYPE_ 1878 ImuMYMag : 1;
SIG_VALTYPE_ 1879 ImuMZMag : 1;

SIG_VALTYPE_ 1696 InputVoltageA              : 1;
SIG_VALTYPE_ 1696 InputCurrentA              : 1;

SIG_VALTYPE_ 1712 InputVoltageB              : 1;
SIG_VALTYPE_ 1712 InputCurrentB              : 1;

SIG_VALTYPE_ 1728 InputVoltageC              : 1;
SIG_VALTYPE_ 1728 InputCurrentC              : 1;

SIG_VALTYPE_ 1744 InputVoltageD              : 1;
SIG_VALTYPE_ 1744 InputCurrentD              : 1;

SIG_VALTYPE_ 1697 OutputVoltageA             : 1;
SIG_VALTYPE_ 1697 OutputCurrentA             : 1;

SIG_VALTYPE_ 1713 OutputVoltageB             : 1;
SIG_VALTYPE_ 1713 OutputCurrentB             : 1;

SIG_VALTYPE_ 1729 OutputVoltageC             : 1;
SIG_VALTYPE_ 1729 OutputCurrentC             : 1;

SIG_VALTYPE_ 1745 OutputVoltageD             : 1;
SIG_VALTYPE_ 1745 OutputCurrentD             : 1;

SIG_VALTYPE_ 1698 MosfetTemperatureA         : 1;
SIG_VALTYPE_ 1698 ControllerTemperatureA     : 1;

SIG_VALTYPE_ 1714 MosfetTemperatureB         : 1;
SIG_VALTYPE_ 1714 ControllerTemperatureB     : 1;

SIG_VALTYPE_ 1730 MosfetTemperatureC         : 1;
SIG_VALTYPE_ 1730 ControllerTemperatureC     : 1;

SIG_VALTYPE_ 1746 MosfetTemperatureD         : 1;
SIG_VALTYPE_ 1746 ControllerTemperatureD     : 1;

SIG_VALTYPE_ 1699 Aux12VA                    : 1;
SIG_VALTYPE_ 1699 Aux3VA                     : 1;

SIG_VALTYPE_ 1715 Aux12VB                    : 1;
SIG_VALTYPE_ 1715 Aux3VB                     : 1;

SIG_VALTYPE_ 1731 Aux12VC                    : 1;
SIG_VALTYPE_ 1731 Aux3VC                     : 1;

SIG_VALTYPE_ 1747 Aux12VD                    : 1;
SIG_VALTYPE_ 1747 Aux3VD                     : 1;

SIG_VALTYPE_ 1700 MaxOutputVoltageLimitA     : 1;
SIG_VALTYPE_ 1700 MaxInputCurrentLimitA      : 1;

SIG_VALTYPE_ 1716 MaxOutputVoltageLimitB     : 1;
SIG_VALTYPE_ 1716 MaxInputCurrentLimitB      : 1;

SIG_VALTYPE_ 1732 MaxOutputVoltageLimitC     : 1;
SIG_VALTYPE_ 1732 MaxInputCurrentLimitC      : 1;

SIG_VALTYPE_ 1748 MaxOutputVoltageLimitD     : 1;
SIG_VALTYPE_ 1748 MaxInputCurrentLimitD      : 1;

SIG_VALTYPE_ 1702 OutputVoltageBattSideA     : 1;
SIG_VALTYPE_ 1702 ConnectorTemperatureA      : 1;

SIG_VALTYPE_ 1718 OutputVoltageBattSideB     : 1;
SIG_VALTYPE_ 1718 ConnectorTemperatureB      : 1;

SIG_VALTYPE_ 1734 OutputVoltageBattSideC     : 1;
SIG_VALTYPE_ 1734 ConnectorTemperatureC      : 1;

SIG_VALTYPE_ 1750 OutputVoltageBattSideD     : 1;
SIG_VALTYPE_ 1750 ConnectorTemperatureD      : 1;

SIG_VALTYPE_ 1706 MaxOutputVoltageCmdA       : 1;
SIG_VALTYPE_ 1722 MaxOutputVoltageCmdB       : 1;
SIG_VALTYPE_ 1738 MaxOutputVoltageCmdC       : 1;
SIG_VALTYPE_ 1754 MaxOutputVoltageCmdD       : 1;

SIG_VALTYPE_ 1707 MaxOutputCurrentCmdA       : 1;
SIG_VALTYPE_ 1723 MaxOutputCurrentCmdB       : 1;
SIG_VALTYPE_ 1739 MaxOutputCurrentCmdC       : 1;
SIG_VALTYPE_ 1755 MaxOutputCurrentCmdD       : 1;
